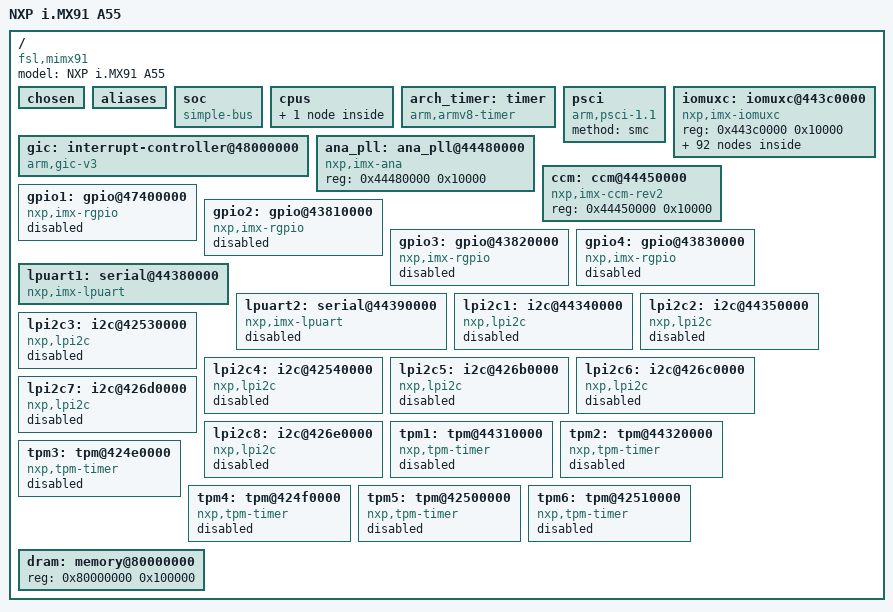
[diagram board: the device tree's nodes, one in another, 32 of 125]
/dts-v1/;

/* node '/' defined in zephyr/dts/common/skeleton.dtsi:9 */
/ {
	#address-cells = < 0x1 >;  /* in zephyr/dts/arm64/nxp/nxp_mimx9111.dtsi:16 */
	#size-cells = < 0x1 >;     /* in zephyr/dts/arm64/nxp/nxp_mimx9111.dtsi:17 */
	model = "NXP i.MX91 A55";  /* in zephyr/boards/nxp/imx91_qsb/imx91_qsb_mimx9111.dts:13 */
	compatible = "fsl,mimx91"; /* in zephyr/boards/nxp/imx91_qsb/imx91_qsb_mimx9111.dts:14 */

	/* node '/chosen' defined in zephyr/dts/common/skeleton.dtsi:13 */
	chosen {
		zephyr,console = &lpuart1;    /* in zephyr/boards/nxp/imx91_qsb/imx91_qsb_mimx9111.dts:17 */
		zephyr,shell-uart = &lpuart1; /* in zephyr/boards/nxp/imx91_qsb/imx91_qsb_mimx9111.dts:18 */
		zephyr,sram = &dram;          /* in zephyr/boards/nxp/imx91_qsb/imx91_qsb_mimx9111.dts:20 */
	};

	/* node '/aliases' defined in zephyr/dts/common/skeleton.dtsi:15 */
	aliases {
	};

	/* node '/soc' defined in zephyr/dts/arm64/armv8-a.dtsi:10 */
	soc {
		#address-cells = < 0x1 >;  /* in zephyr/dts/arm64/armv8-a.dtsi:11 */
		#size-cells = < 0x1 >;     /* in zephyr/dts/arm64/armv8-a.dtsi:12 */
		compatible = "simple-bus"; /* in zephyr/dts/arm64/armv8-a.dtsi:13 */
		ranges;                    /* in zephyr/dts/arm64/armv8-a.dtsi:14 */
	};

	/* node '/cpus' defined in zephyr/dts/arm64/nxp/nxp_mimx9111.dtsi:19 */
	cpus {
		#address-cells = < 0x1 >; /* in zephyr/dts/arm64/nxp/nxp_mimx9111.dtsi:20 */
		#size-cells = < 0x0 >;    /* in zephyr/dts/arm64/nxp/nxp_mimx9111.dtsi:21 */

		/* node '/cpus/cpu@0' defined in zephyr/dts/arm64/nxp/nxp_mimx9111.dtsi:23 */
		cpu@0 {
			device_type = "cpu";           /* in zephyr/dts/arm64/nxp/nxp_mimx9111.dtsi:24 */
			compatible = "arm,cortex-a55"; /* in zephyr/dts/arm64/nxp/nxp_mimx9111.dtsi:25 */
			reg = < 0x0 >;                 /* in zephyr/dts/arm64/nxp/nxp_mimx9111.dtsi:26 */
		};
	};

	/* node '/timer' defined in zephyr/dts/arm64/nxp/nxp_mimx9111.dtsi:30 */
	arch_timer: timer {
		compatible = "arm,armv8-timer";    /* in zephyr/dts/arm64/nxp/nxp_mimx9111.dtsi:31 */
		interrupts = < 0x1 0xd 0x2 0xa0 >,
		             < 0x1 0xe 0x2 0xa0 >,
		             < 0x1 0xb 0x2 0xa0 >,
		             < 0x1 0xa 0x2 0xa0 >; /* in zephyr/dts/arm64/nxp/nxp_mimx9111.dtsi:32 */
		interrupt-parent = < &gic >;       /* in zephyr/dts/arm64/nxp/nxp_mimx9111.dtsi:40 */
	};

	/* node '/psci' defined in zephyr/dts/arm64/nxp/nxp_mimx9111.dtsi:43 */
	psci: psci {
		compatible = "arm,psci-1.1"; /* in zephyr/dts/arm64/nxp/nxp_mimx9111.dtsi:44 */
		method = "smc";              /* in zephyr/dts/arm64/nxp/nxp_mimx9111.dtsi:45 */
	};

	/* node '/interrupt-controller@48000000' defined in zephyr/dts/arm64/nxp/nxp_mimx9111.dtsi:48 */
	gic: interrupt-controller@48000000 {
		compatible = "arm,gic-v3",
		             "arm,gic";       /* in zephyr/dts/arm64/nxp/nxp_mimx9111.dtsi:49 */
		reg = < 0x48000000 0x10000 >,
		      < 0x48040000 0xc0000 >; /* in zephyr/dts/arm64/nxp/nxp_mimx9111.dtsi:50 */
		interrupt-controller;         /* in zephyr/dts/arm64/nxp/nxp_mimx9111.dtsi:52 */
		#interrupt-cells = < 0x4 >;   /* in zephyr/dts/arm64/nxp/nxp_mimx9111.dtsi:53 */
		status = "okay";              /* in zephyr/dts/arm64/nxp/nxp_mimx9111.dtsi:54 */
		phandle = < 0x1 >;            /* in zephyr/dts/arm64/nxp/nxp_mimx9111.dtsi:40 */
	};

	/* node '/iomuxc@443c0000' defined in zephyr/dts/arm64/nxp/nxp_mimx9111.dtsi:57 */
	iomuxc: iomuxc@443c0000 {
		compatible = "nxp,imx-iomuxc"; /* in zephyr/dts/arm64/nxp/nxp_mimx9111.dtsi:58 */
		reg = < 0x443c0000 0x10000 >;  /* in zephyr/dts/arm64/nxp/nxp_mimx9111.dtsi:59 */
		status = "okay";               /* in zephyr/dts/arm64/nxp/nxp_mimx9111.dtsi:60 */

		/* node '/iomuxc@443c0000/pinctrl' defined in zephyr/dts/arm64/nxp/nxp_mimx9111.dtsi:62 */
		pinctrl: pinctrl {
			compatible = "nxp,imx93-pinctrl"; /* in zephyr/dts/arm64/nxp/nxp_mimx9111.dtsi:63 */
			status = "okay";                  /* in zephyr/dts/arm64/nxp/nxp_mimx9111.dtsi:64 */

			/* node '/iomuxc@443c0000/pinctrl/uart1_default' defined in zephyr/boards/nxp/imx91_qsb/imx91_qsb-pinctrl.dtsi:10 */
			uart1_default: uart1_default {
				phandle = < 0x5a >; /* in zephyr/boards/nxp/imx91_qsb/imx91_qsb_mimx9111.dts:32 */

				/* node '/iomuxc@443c0000/pinctrl/uart1_default/group0' defined in zephyr/boards/nxp/imx91_qsb/imx91_qsb-pinctrl.dtsi:11 */
				group0 {
					pinmux = < &iomuxc1_uart1_rxd_lpuart_rx_lpuart1_rx >,
					         < &iomuxc1_uart1_txd_lpuart_tx_lpuart1_tx >; /* in zephyr/boards/nxp/imx91_qsb/imx91_qsb-pinctrl.dtsi:12 */
					bias-pull-up;                                         /* in zephyr/boards/nxp/imx91_qsb/imx91_qsb-pinctrl.dtsi:14 */
					slew-rate = "slightly_fast";                          /* in zephyr/boards/nxp/imx91_qsb/imx91_qsb-pinctrl.dtsi:15 */
					drive-strength = "x5";                                /* in zephyr/boards/nxp/imx91_qsb/imx91_qsb-pinctrl.dtsi:16 */
				};
			};

			/* node '/iomuxc@443c0000/pinctrl/uart2_default' defined in zephyr/boards/nxp/imx91_qsb/imx91_qsb-pinctrl.dtsi:20 */
			uart2_default: uart2_default {

				/* node '/iomuxc@443c0000/pinctrl/uart2_default/group0' defined in zephyr/boards/nxp/imx91_qsb/imx91_qsb-pinctrl.dtsi:21 */
				group0 {
					pinmux = < &iomuxc1_uart2_rxd_lpuart_rx_lpuart2_rx >,
					         < &iomuxc1_uart2_txd_lpuart_tx_lpuart2_tx >; /* in zephyr/boards/nxp/imx91_qsb/imx91_qsb-pinctrl.dtsi:22 */
					bias-pull-up;                                         /* in zephyr/boards/nxp/imx91_qsb/imx91_qsb-pinctrl.dtsi:24 */
					slew-rate = "slightly_fast";                          /* in zephyr/boards/nxp/imx91_qsb/imx91_qsb-pinctrl.dtsi:25 */
					drive-strength = "x5";                                /* in zephyr/boards/nxp/imx91_qsb/imx91_qsb-pinctrl.dtsi:26 */
				};
			};
		};

		/* node '/iomuxc@443c0000/IOMUXC1_CCM_CLKO1_GPIO_IO_GPIO3_IO26' defined in modules/hal/nxp/dts/nxp/nxp_imx/mimx9111cvxxj-pinctrl.dtsi:26 */
		iomuxc1_ccm_clko1_gpio_io_gpio3_io26: IOMUXC1_CCM_CLKO1_GPIO_IO_GPIO3_IO26 {
			pinmux = < 0x443c0088 0x5 0x0 0x0 0x443c0238 >; /* in modules/hal/nxp/dts/nxp/nxp_imx/mimx9111cvxxj-pinctrl.dtsi:27 */
			phandle = < 0x46 >;                             /* in zephyr/dts/arm64/nxp/nxp_mimx9111.dtsi:355 */
		};

		/* node '/iomuxc@443c0000/IOMUXC1_DAP_TCLK_SWCLK_GPIO_IO_GPIO3_IO30' defined in modules/hal/nxp/dts/nxp/nxp_imx/mimx9111cvxxj-pinctrl.dtsi:32 */
		iomuxc1_dap_tclk_swclk_gpio_io_gpio3_io30: IOMUXC1_DAP_TCLK_SWCLK_GPIO_IO_GPIO3_IO30 {
			pinmux = < 0x443c0008 0x5 0x0 0x0 0x443c01b8 >; /* in modules/hal/nxp/dts/nxp/nxp_imx/mimx9111cvxxj-pinctrl.dtsi:33 */
			phandle = < 0x49 >;                             /* in zephyr/dts/arm64/nxp/nxp_mimx9111.dtsi:355 */
		};

		/* node '/iomuxc@443c0000/IOMUXC1_DAP_TDI_GPIO_IO_GPIO3_IO28' defined in modules/hal/nxp/dts/nxp/nxp_imx/mimx9111cvxxj-pinctrl.dtsi:47 */
		iomuxc1_dap_tdi_gpio_io_gpio3_io28: IOMUXC1_DAP_TDI_GPIO_IO_GPIO3_IO28 {
			pinmux = < 0x443c0000 0x5 0x0 0x0 0x443c01b0 >; /* in modules/hal/nxp/dts/nxp/nxp_imx/mimx9111cvxxj-pinctrl.dtsi:48 */
			phandle = < 0x47 >;                             /* in zephyr/dts/arm64/nxp/nxp_mimx9111.dtsi:355 */
		};

		/* node '/iomuxc@443c0000/IOMUXC1_DAP_TDO_TRACESWO_GPIO_IO_GPIO3_IO31' defined in modules/hal/nxp/dts/nxp/nxp_imx/mimx9111cvxxj-pinctrl.dtsi:65 */
		iomuxc1_dap_tdo_traceswo_gpio_io_gpio3_io31: IOMUXC1_DAP_TDO_TRACESWO_GPIO_IO_GPIO3_IO31 {
			pinmux = < 0x443c000c 0x5 0x0 0x0 0x443c01bc >; /* in modules/hal/nxp/dts/nxp/nxp_imx/mimx9111cvxxj-pinctrl.dtsi:66 */
			phandle = < 0x4a >;                             /* in zephyr/dts/arm64/nxp/nxp_mimx9111.dtsi:355 */
		};

		/* node '/iomuxc@443c0000/IOMUXC1_DAP_TMS_SWDIO_GPIO_IO_GPIO3_IO29' defined in modules/hal/nxp/dts/nxp/nxp_imx/mimx9111cvxxj-pinctrl.dtsi:80 */
		iomuxc1_dap_tms_swdio_gpio_io_gpio3_io29: IOMUXC1_DAP_TMS_SWDIO_GPIO_IO_GPIO3_IO29 {
			pinmux = < 0x443c0004 0x5 0x0 0x0 0x443c01b4 >; /* in modules/hal/nxp/dts/nxp/nxp_imx/mimx9111cvxxj-pinctrl.dtsi:81 */
			phandle = < 0x48 >;                             /* in zephyr/dts/arm64/nxp/nxp_mimx9111.dtsi:355 */
		};

		/* node '/iomuxc@443c0000/IOMUXC1_ENET1_MDC_GPIO_IO_GPIO4_IO0' defined in modules/hal/nxp/dts/nxp/nxp_imx/mimx9111cvxxj-pinctrl.dtsi:95 */
		iomuxc1_enet1_mdc_gpio_io_gpio4_io0: IOMUXC1_ENET1_MDC_GPIO_IO_GPIO4_IO0 {
			pinmux = < 0x443c0098 0x5 0x0 0x0 0x443c0248 >; /* in modules/hal/nxp/dts/nxp/nxp_imx/mimx9111cvxxj-pinctrl.dtsi:96 */
			phandle = < 0x4b >;                             /* in zephyr/dts/arm64/nxp/nxp_mimx9111.dtsi:390 */
		};

		/* node '/iomuxc@443c0000/IOMUXC1_ENET1_MDIO_GPIO_IO_GPIO4_IO1' defined in modules/hal/nxp/dts/nxp/nxp_imx/mimx9111cvxxj-pinctrl.dtsi:116 */
		iomuxc1_enet1_mdio_gpio_io_gpio4_io1: IOMUXC1_ENET1_MDIO_GPIO_IO_GPIO4_IO1 {
			pinmux = < 0x443c009c 0x5 0x0 0x0 0x443c024c >; /* in modules/hal/nxp/dts/nxp/nxp_imx/mimx9111cvxxj-pinctrl.dtsi:117 */
			phandle = < 0x4c >;                             /* in zephyr/dts/arm64/nxp/nxp_mimx9111.dtsi:390 */
		};

		/* node '/iomuxc@443c0000/IOMUXC1_ENET1_RD0_GPIO_IO_GPIO4_IO10' defined in modules/hal/nxp/dts/nxp/nxp_imx/mimx9111cvxxj-pinctrl.dtsi:137 */
		iomuxc1_enet1_rd0_gpio_io_gpio4_io10: IOMUXC1_ENET1_RD0_GPIO_IO_GPIO4_IO10 {
			pinmux = < 0x443c00c0 0x5 0x0 0x0 0x443c0270 >; /* in modules/hal/nxp/dts/nxp/nxp_imx/mimx9111cvxxj-pinctrl.dtsi:138 */
			phandle = < 0x55 >;                             /* in zephyr/dts/arm64/nxp/nxp_mimx9111.dtsi:390 */
		};

		/* node '/iomuxc@443c0000/IOMUXC1_ENET1_RD1_GPIO_IO_GPIO4_IO11' defined in modules/hal/nxp/dts/nxp/nxp_imx/mimx9111cvxxj-pinctrl.dtsi:149 */
		iomuxc1_enet1_rd1_gpio_io_gpio4_io11: IOMUXC1_ENET1_RD1_GPIO_IO_GPIO4_IO11 {
			pinmux = < 0x443c00c4 0x5 0x0 0x0 0x443c0274 >; /* in modules/hal/nxp/dts/nxp/nxp_imx/mimx9111cvxxj-pinctrl.dtsi:150 */
			phandle = < 0x56 >;                             /* in zephyr/dts/arm64/nxp/nxp_mimx9111.dtsi:390 */
		};

		/* node '/iomuxc@443c0000/IOMUXC1_ENET1_RD2_GPIO_IO_GPIO4_IO12' defined in modules/hal/nxp/dts/nxp/nxp_imx/mimx9111cvxxj-pinctrl.dtsi:164 */
		iomuxc1_enet1_rd2_gpio_io_gpio4_io12: IOMUXC1_ENET1_RD2_GPIO_IO_GPIO4_IO12 {
			pinmux = < 0x443c00c8 0x5 0x0 0x0 0x443c0278 >; /* in modules/hal/nxp/dts/nxp/nxp_imx/mimx9111cvxxj-pinctrl.dtsi:165 */
			phandle = < 0x57 >;                             /* in zephyr/dts/arm64/nxp/nxp_mimx9111.dtsi:390 */
		};

		/* node '/iomuxc@443c0000/IOMUXC1_ENET1_RD3_GPIO_IO_GPIO4_IO13' defined in modules/hal/nxp/dts/nxp/nxp_imx/mimx9111cvxxj-pinctrl.dtsi:176 */
		iomuxc1_enet1_rd3_gpio_io_gpio4_io13: IOMUXC1_ENET1_RD3_GPIO_IO_GPIO4_IO13 {
			pinmux = < 0x443c00cc 0x5 0x0 0x0 0x443c027c >; /* in modules/hal/nxp/dts/nxp/nxp_imx/mimx9111cvxxj-pinctrl.dtsi:177 */
			phandle = < 0x58 >;                             /* in zephyr/dts/arm64/nxp/nxp_mimx9111.dtsi:390 */
		};

		/* node '/iomuxc@443c0000/IOMUXC1_ENET1_RXC_GPIO_IO_GPIO4_IO9' defined in modules/hal/nxp/dts/nxp/nxp_imx/mimx9111cvxxj-pinctrl.dtsi:191 */
		iomuxc1_enet1_rxc_gpio_io_gpio4_io9: IOMUXC1_ENET1_RXC_GPIO_IO_GPIO4_IO9 {
			pinmux = < 0x443c00bc 0x5 0x0 0x0 0x443c026c >; /* in modules/hal/nxp/dts/nxp/nxp_imx/mimx9111cvxxj-pinctrl.dtsi:192 */
			phandle = < 0x54 >;                             /* in zephyr/dts/arm64/nxp/nxp_mimx9111.dtsi:390 */
		};

		/* node '/iomuxc@443c0000/IOMUXC1_ENET1_RX_CTL_GPIO_IO_GPIO4_IO8' defined in modules/hal/nxp/dts/nxp/nxp_imx/mimx9111cvxxj-pinctrl.dtsi:203 */
		iomuxc1_enet1_rx_ctl_gpio_io_gpio4_io8: IOMUXC1_ENET1_RX_CTL_GPIO_IO_GPIO4_IO8 {
			pinmux = < 0x443c00b8 0x5 0x0 0x0 0x443c0268 >; /* in modules/hal/nxp/dts/nxp/nxp_imx/mimx9111cvxxj-pinctrl.dtsi:204 */
			phandle = < 0x53 >;                             /* in zephyr/dts/arm64/nxp/nxp_mimx9111.dtsi:390 */
		};

		/* node '/iomuxc@443c0000/IOMUXC1_ENET1_TD0_GPIO_IO_GPIO4_IO5' defined in modules/hal/nxp/dts/nxp/nxp_imx/mimx9111cvxxj-pinctrl.dtsi:221 */
		iomuxc1_enet1_td0_gpio_io_gpio4_io5: IOMUXC1_ENET1_TD0_GPIO_IO_GPIO4_IO5 {
			pinmux = < 0x443c00ac 0x5 0x0 0x0 0x443c025c >; /* in modules/hal/nxp/dts/nxp/nxp_imx/mimx9111cvxxj-pinctrl.dtsi:222 */
			phandle = < 0x50 >;                             /* in zephyr/dts/arm64/nxp/nxp_mimx9111.dtsi:390 */
		};

		/* node '/iomuxc@443c0000/IOMUXC1_ENET1_TD1_GPIO_IO_GPIO4_IO4' defined in modules/hal/nxp/dts/nxp/nxp_imx/mimx9111cvxxj-pinctrl.dtsi:233 */
		iomuxc1_enet1_td1_gpio_io_gpio4_io4: IOMUXC1_ENET1_TD1_GPIO_IO_GPIO4_IO4 {
			pinmux = < 0x443c00a8 0x5 0x0 0x0 0x443c0258 >; /* in modules/hal/nxp/dts/nxp/nxp_imx/mimx9111cvxxj-pinctrl.dtsi:234 */
			phandle = < 0x4f >;                             /* in zephyr/dts/arm64/nxp/nxp_mimx9111.dtsi:390 */
		};

		/* node '/iomuxc@443c0000/IOMUXC1_ENET1_TD2_GPIO_IO_GPIO4_IO3' defined in modules/hal/nxp/dts/nxp/nxp_imx/mimx9111cvxxj-pinctrl.dtsi:260 */
		iomuxc1_enet1_td2_gpio_io_gpio4_io3: IOMUXC1_ENET1_TD2_GPIO_IO_GPIO4_IO3 {
			pinmux = < 0x443c00a4 0x5 0x0 0x0 0x443c0254 >; /* in modules/hal/nxp/dts/nxp/nxp_imx/mimx9111cvxxj-pinctrl.dtsi:261 */
			phandle = < 0x4e >;                             /* in zephyr/dts/arm64/nxp/nxp_mimx9111.dtsi:390 */
		};

		/* node '/iomuxc@443c0000/IOMUXC1_ENET1_TD3_GPIO_IO_GPIO4_IO2' defined in modules/hal/nxp/dts/nxp/nxp_imx/mimx9111cvxxj-pinctrl.dtsi:278 */
		iomuxc1_enet1_td3_gpio_io_gpio4_io2: IOMUXC1_ENET1_TD3_GPIO_IO_GPIO4_IO2 {
			pinmux = < 0x443c00a0 0x5 0x0 0x0 0x443c0250 >; /* in modules/hal/nxp/dts/nxp/nxp_imx/mimx9111cvxxj-pinctrl.dtsi:279 */
			phandle = < 0x4d >;                             /* in zephyr/dts/arm64/nxp/nxp_mimx9111.dtsi:390 */
		};

		/* node '/iomuxc@443c0000/IOMUXC1_ENET1_TXC_GPIO_IO_GPIO4_IO7' defined in modules/hal/nxp/dts/nxp/nxp_imx/mimx9111cvxxj-pinctrl.dtsi:296 */
		iomuxc1_enet1_txc_gpio_io_gpio4_io7: IOMUXC1_ENET1_TXC_GPIO_IO_GPIO4_IO7 {
			pinmux = < 0x443c00b4 0x5 0x0 0x0 0x443c0264 >; /* in modules/hal/nxp/dts/nxp/nxp_imx/mimx9111cvxxj-pinctrl.dtsi:297 */
			phandle = < 0x52 >;                             /* in zephyr/dts/arm64/nxp/nxp_mimx9111.dtsi:390 */
		};

		/* node '/iomuxc@443c0000/IOMUXC1_ENET1_TX_CTL_GPIO_IO_GPIO4_IO6' defined in modules/hal/nxp/dts/nxp/nxp_imx/mimx9111cvxxj-pinctrl.dtsi:308 */
		iomuxc1_enet1_tx_ctl_gpio_io_gpio4_io6: IOMUXC1_ENET1_TX_CTL_GPIO_IO_GPIO4_IO6 {
			pinmux = < 0x443c00b0 0x5 0x0 0x0 0x443c0260 >; /* in modules/hal/nxp/dts/nxp/nxp_imx/mimx9111cvxxj-pinctrl.dtsi:309 */
			phandle = < 0x51 >;                             /* in zephyr/dts/arm64/nxp/nxp_mimx9111.dtsi:390 */
		};

		/* node '/iomuxc@443c0000/IOMUXC1_GPIO_IO00_GPIO_IO_GPIO2_IO0' defined in modules/hal/nxp/dts/nxp/nxp_imx/mimx9111cvxxj-pinctrl.dtsi:320 */
		iomuxc1_gpio_io00_gpio_io_gpio2_io0: IOMUXC1_GPIO_IO00_GPIO_IO_GPIO2_IO0 {
			pinmux = < 0x443c0010 0x0 0x0 0x0 0x443c01c0 >; /* in modules/hal/nxp/dts/nxp/nxp_imx/mimx9111cvxxj-pinctrl.dtsi:321 */
			phandle = < 0x16 >;                             /* in zephyr/dts/arm64/nxp/nxp_mimx9111.dtsi:330 */
		};

		/* node '/iomuxc@443c0000/IOMUXC1_GPIO_IO01_GPIO_IO_GPIO2_IO1' defined in modules/hal/nxp/dts/nxp/nxp_imx/mimx9111cvxxj-pinctrl.dtsi:344 */
		iomuxc1_gpio_io01_gpio_io_gpio2_io1: IOMUXC1_GPIO_IO01_GPIO_IO_GPIO2_IO1 {
			pinmux = < 0x443c0014 0x0 0x0 0x0 0x443c01c4 >; /* in modules/hal/nxp/dts/nxp/nxp_imx/mimx9111cvxxj-pinctrl.dtsi:345 */
			phandle = < 0x17 >;                             /* in zephyr/dts/arm64/nxp/nxp_mimx9111.dtsi:330 */
		};

		/* node '/iomuxc@443c0000/IOMUXC1_GPIO_IO02_GPIO_IO_GPIO2_IO2' defined in modules/hal/nxp/dts/nxp/nxp_imx/mimx9111cvxxj-pinctrl.dtsi:368 */
		iomuxc1_gpio_io02_gpio_io_gpio2_io2: IOMUXC1_GPIO_IO02_GPIO_IO_GPIO2_IO2 {
			pinmux = < 0x443c0018 0x0 0x0 0x0 0x443c01c8 >; /* in modules/hal/nxp/dts/nxp/nxp_imx/mimx9111cvxxj-pinctrl.dtsi:369 */
			phandle = < 0x18 >;                             /* in zephyr/dts/arm64/nxp/nxp_mimx9111.dtsi:330 */
		};

		/* node '/iomuxc@443c0000/IOMUXC1_GPIO_IO03_GPIO_IO_GPIO2_IO3' defined in modules/hal/nxp/dts/nxp/nxp_imx/mimx9111cvxxj-pinctrl.dtsi:392 */
		iomuxc1_gpio_io03_gpio_io_gpio2_io3: IOMUXC1_GPIO_IO03_GPIO_IO_GPIO2_IO3 {
			pinmux = < 0x443c001c 0x0 0x0 0x0 0x443c01cc >; /* in modules/hal/nxp/dts/nxp/nxp_imx/mimx9111cvxxj-pinctrl.dtsi:393 */
			phandle = < 0x19 >;                             /* in zephyr/dts/arm64/nxp/nxp_mimx9111.dtsi:330 */
		};

		/* node '/iomuxc@443c0000/IOMUXC1_GPIO_IO04_GPIO_IO_GPIO2_IO4' defined in modules/hal/nxp/dts/nxp/nxp_imx/mimx9111cvxxj-pinctrl.dtsi:416 */
		iomuxc1_gpio_io04_gpio_io_gpio2_io4: IOMUXC1_GPIO_IO04_GPIO_IO_GPIO2_IO4 {
			pinmux = < 0x443c0020 0x0 0x0 0x0 0x443c01d0 >; /* in modules/hal/nxp/dts/nxp/nxp_imx/mimx9111cvxxj-pinctrl.dtsi:417 */
			phandle = < 0x1a >;                             /* in zephyr/dts/arm64/nxp/nxp_mimx9111.dtsi:330 */
		};

		/* node '/iomuxc@443c0000/IOMUXC1_GPIO_IO05_GPIO_IO_GPIO2_IO5' defined in modules/hal/nxp/dts/nxp/nxp_imx/mimx9111cvxxj-pinctrl.dtsi:440 */
		iomuxc1_gpio_io05_gpio_io_gpio2_io5: IOMUXC1_GPIO_IO05_GPIO_IO_GPIO2_IO5 {
			pinmux = < 0x443c0024 0x0 0x0 0x0 0x443c01d4 >; /* in modules/hal/nxp/dts/nxp/nxp_imx/mimx9111cvxxj-pinctrl.dtsi:441 */
			phandle = < 0x1b >;                             /* in zephyr/dts/arm64/nxp/nxp_mimx9111.dtsi:330 */
		};

		/* node '/iomuxc@443c0000/IOMUXC1_GPIO_IO06_GPIO_IO_GPIO2_IO6' defined in modules/hal/nxp/dts/nxp/nxp_imx/mimx9111cvxxj-pinctrl.dtsi:464 */
		iomuxc1_gpio_io06_gpio_io_gpio2_io6: IOMUXC1_GPIO_IO06_GPIO_IO_GPIO2_IO6 {
			pinmux = < 0x443c0028 0x0 0x0 0x0 0x443c01d8 >; /* in modules/hal/nxp/dts/nxp/nxp_imx/mimx9111cvxxj-pinctrl.dtsi:465 */
			phandle = < 0x1c >;                             /* in zephyr/dts/arm64/nxp/nxp_mimx9111.dtsi:330 */
		};

		/* node '/iomuxc@443c0000/IOMUXC1_GPIO_IO07_GPIO_IO_GPIO2_IO7' defined in modules/hal/nxp/dts/nxp/nxp_imx/mimx9111cvxxj-pinctrl.dtsi:488 */
		iomuxc1_gpio_io07_gpio_io_gpio2_io7: IOMUXC1_GPIO_IO07_GPIO_IO_GPIO2_IO7 {
			pinmux = < 0x443c002c 0x0 0x0 0x0 0x443c01dc >; /* in modules/hal/nxp/dts/nxp/nxp_imx/mimx9111cvxxj-pinctrl.dtsi:489 */
			phandle = < 0x1d >;                             /* in zephyr/dts/arm64/nxp/nxp_mimx9111.dtsi:330 */
		};

		/* node '/iomuxc@443c0000/IOMUXC1_GPIO_IO08_GPIO_IO_GPIO2_IO8' defined in modules/hal/nxp/dts/nxp/nxp_imx/mimx9111cvxxj-pinctrl.dtsi:512 */
		iomuxc1_gpio_io08_gpio_io_gpio2_io8: IOMUXC1_GPIO_IO08_GPIO_IO_GPIO2_IO8 {
			pinmux = < 0x443c0030 0x0 0x0 0x0 0x443c01e0 >; /* in modules/hal/nxp/dts/nxp/nxp_imx/mimx9111cvxxj-pinctrl.dtsi:513 */
			phandle = < 0x1e >;                             /* in zephyr/dts/arm64/nxp/nxp_mimx9111.dtsi:330 */
		};

		/* node '/iomuxc@443c0000/IOMUXC1_GPIO_IO09_GPIO_IO_GPIO2_IO9' defined in modules/hal/nxp/dts/nxp/nxp_imx/mimx9111cvxxj-pinctrl.dtsi:536 */
		iomuxc1_gpio_io09_gpio_io_gpio2_io9: IOMUXC1_GPIO_IO09_GPIO_IO_GPIO2_IO9 {
			pinmux = < 0x443c0034 0x0 0x0 0x0 0x443c01e4 >; /* in modules/hal/nxp/dts/nxp/nxp_imx/mimx9111cvxxj-pinctrl.dtsi:537 */
			phandle = < 0x1f >;                             /* in zephyr/dts/arm64/nxp/nxp_mimx9111.dtsi:330 */
		};

		/* node '/iomuxc@443c0000/IOMUXC1_GPIO_IO10_GPIO_IO_GPIO2_IO10' defined in modules/hal/nxp/dts/nxp/nxp_imx/mimx9111cvxxj-pinctrl.dtsi:560 */
		iomuxc1_gpio_io10_gpio_io_gpio2_io10: IOMUXC1_GPIO_IO10_GPIO_IO_GPIO2_IO10 {
			pinmux = < 0x443c0038 0x0 0x0 0x0 0x443c01e8 >; /* in modules/hal/nxp/dts/nxp/nxp_imx/mimx9111cvxxj-pinctrl.dtsi:561 */
			phandle = < 0x20 >;                             /* in zephyr/dts/arm64/nxp/nxp_mimx9111.dtsi:330 */
		};

		/* node '/iomuxc@443c0000/IOMUXC1_GPIO_IO11_GPIO_IO_GPIO2_IO11' defined in modules/hal/nxp/dts/nxp/nxp_imx/mimx9111cvxxj-pinctrl.dtsi:584 */
		iomuxc1_gpio_io11_gpio_io_gpio2_io11: IOMUXC1_GPIO_IO11_GPIO_IO_GPIO2_IO11 {
			pinmux = < 0x443c003c 0x0 0x0 0x0 0x443c01ec >; /* in modules/hal/nxp/dts/nxp/nxp_imx/mimx9111cvxxj-pinctrl.dtsi:585 */
			phandle = < 0x21 >;                             /* in zephyr/dts/arm64/nxp/nxp_mimx9111.dtsi:330 */
		};

		/* node '/iomuxc@443c0000/IOMUXC1_GPIO_IO12_GPIO_IO_GPIO2_IO12' defined in modules/hal/nxp/dts/nxp/nxp_imx/mimx9111cvxxj-pinctrl.dtsi:605 */
		iomuxc1_gpio_io12_gpio_io_gpio2_io12: IOMUXC1_GPIO_IO12_GPIO_IO_GPIO2_IO12 {
			pinmux = < 0x443c0040 0x0 0x0 0x0 0x443c01f0 >; /* in modules/hal/nxp/dts/nxp/nxp_imx/mimx9111cvxxj-pinctrl.dtsi:606 */
			phandle = < 0x22 >;                             /* in zephyr/dts/arm64/nxp/nxp_mimx9111.dtsi:330 */
		};

		/* node '/iomuxc@443c0000/IOMUXC1_GPIO_IO13_GPIO_IO_GPIO2_IO13' defined in modules/hal/nxp/dts/nxp/nxp_imx/mimx9111cvxxj-pinctrl.dtsi:632 */
		iomuxc1_gpio_io13_gpio_io_gpio2_io13: IOMUXC1_GPIO_IO13_GPIO_IO_GPIO2_IO13 {
			pinmux = < 0x443c0044 0x0 0x0 0x0 0x443c01f4 >; /* in modules/hal/nxp/dts/nxp/nxp_imx/mimx9111cvxxj-pinctrl.dtsi:633 */
			phandle = < 0x23 >;                             /* in zephyr/dts/arm64/nxp/nxp_mimx9111.dtsi:330 */
		};

		/* node '/iomuxc@443c0000/IOMUXC1_GPIO_IO14_GPIO_IO_GPIO2_IO14' defined in modules/hal/nxp/dts/nxp/nxp_imx/mimx9111cvxxj-pinctrl.dtsi:656 */
		iomuxc1_gpio_io14_gpio_io_gpio2_io14: IOMUXC1_GPIO_IO14_GPIO_IO_GPIO2_IO14 {
			pinmux = < 0x443c0048 0x0 0x0 0x0 0x443c01f8 >; /* in modules/hal/nxp/dts/nxp/nxp_imx/mimx9111cvxxj-pinctrl.dtsi:657 */
			phandle = < 0x24 >;                             /* in zephyr/dts/arm64/nxp/nxp_mimx9111.dtsi:330 */
		};

		/* node '/iomuxc@443c0000/IOMUXC1_GPIO_IO15_GPIO_IO_GPIO2_IO15' defined in modules/hal/nxp/dts/nxp/nxp_imx/mimx9111cvxxj-pinctrl.dtsi:680 */
		iomuxc1_gpio_io15_gpio_io_gpio2_io15: IOMUXC1_GPIO_IO15_GPIO_IO_GPIO2_IO15 {
			pinmux = < 0x443c004c 0x0 0x0 0x0 0x443c01fc >; /* in modules/hal/nxp/dts/nxp/nxp_imx/mimx9111cvxxj-pinctrl.dtsi:681 */
			phandle = < 0x25 >;                             /* in zephyr/dts/arm64/nxp/nxp_mimx9111.dtsi:330 */
		};

		/* node '/iomuxc@443c0000/IOMUXC1_GPIO_IO16_GPIO_IO_GPIO2_IO16' defined in modules/hal/nxp/dts/nxp/nxp_imx/mimx9111cvxxj-pinctrl.dtsi:704 */
		iomuxc1_gpio_io16_gpio_io_gpio2_io16: IOMUXC1_GPIO_IO16_GPIO_IO_GPIO2_IO16 {
			pinmux = < 0x443c0050 0x0 0x0 0x0 0x443c0200 >; /* in modules/hal/nxp/dts/nxp/nxp_imx/mimx9111cvxxj-pinctrl.dtsi:705 */
			phandle = < 0x26 >;                             /* in zephyr/dts/arm64/nxp/nxp_mimx9111.dtsi:330 */
		};

		/* node '/iomuxc@443c0000/IOMUXC1_GPIO_IO17_GPIO_IO_GPIO2_IO17' defined in modules/hal/nxp/dts/nxp/nxp_imx/mimx9111cvxxj-pinctrl.dtsi:728 */
		iomuxc1_gpio_io17_gpio_io_gpio2_io17: IOMUXC1_GPIO_IO17_GPIO_IO_GPIO2_IO17 {
			pinmux = < 0x443c0054 0x0 0x0 0x0 0x443c0204 >; /* in modules/hal/nxp/dts/nxp/nxp_imx/mimx9111cvxxj-pinctrl.dtsi:729 */
			phandle = < 0x27 >;                             /* in zephyr/dts/arm64/nxp/nxp_mimx9111.dtsi:330 */
		};

		/* node '/iomuxc@443c0000/IOMUXC1_GPIO_IO18_GPIO_IO_GPIO2_IO18' defined in modules/hal/nxp/dts/nxp/nxp_imx/mimx9111cvxxj-pinctrl.dtsi:752 */
		iomuxc1_gpio_io18_gpio_io_gpio2_io18: IOMUXC1_GPIO_IO18_GPIO_IO_GPIO2_IO18 {
			pinmux = < 0x443c0058 0x0 0x0 0x0 0x443c0208 >; /* in modules/hal/nxp/dts/nxp/nxp_imx/mimx9111cvxxj-pinctrl.dtsi:753 */
			phandle = < 0x28 >;                             /* in zephyr/dts/arm64/nxp/nxp_mimx9111.dtsi:330 */
		};

		/* node '/iomuxc@443c0000/IOMUXC1_GPIO_IO19_GPIO_IO_GPIO2_IO19' defined in modules/hal/nxp/dts/nxp/nxp_imx/mimx9111cvxxj-pinctrl.dtsi:773 */
		iomuxc1_gpio_io19_gpio_io_gpio2_io19: IOMUXC1_GPIO_IO19_GPIO_IO_GPIO2_IO19 {
			pinmux = < 0x443c005c 0x0 0x0 0x0 0x443c020c >; /* in modules/hal/nxp/dts/nxp/nxp_imx/mimx9111cvxxj-pinctrl.dtsi:774 */
			phandle = < 0x29 >;                             /* in zephyr/dts/arm64/nxp/nxp_mimx9111.dtsi:330 */
		};

		/* node '/iomuxc@443c0000/IOMUXC1_GPIO_IO20_GPIO_IO_GPIO2_IO20' defined in modules/hal/nxp/dts/nxp/nxp_imx/mimx9111cvxxj-pinctrl.dtsi:800 */
		iomuxc1_gpio_io20_gpio_io_gpio2_io20: IOMUXC1_GPIO_IO20_GPIO_IO_GPIO2_IO20 {
			pinmux = < 0x443c0060 0x0 0x0 0x0 0x443c0210 >; /* in modules/hal/nxp/dts/nxp/nxp_imx/mimx9111cvxxj-pinctrl.dtsi:801 */
			phandle = < 0x2a >;                             /* in zephyr/dts/arm64/nxp/nxp_mimx9111.dtsi:330 */
		};

		/* node '/iomuxc@443c0000/IOMUXC1_GPIO_IO21_GPIO_IO_GPIO2_IO21' defined in modules/hal/nxp/dts/nxp/nxp_imx/mimx9111cvxxj-pinctrl.dtsi:821 */
		iomuxc1_gpio_io21_gpio_io_gpio2_io21: IOMUXC1_GPIO_IO21_GPIO_IO_GPIO2_IO21 {
			pinmux = < 0x443c0064 0x0 0x0 0x0 0x443c0214 >; /* in modules/hal/nxp/dts/nxp/nxp_imx/mimx9111cvxxj-pinctrl.dtsi:822 */
			phandle = < 0x2b >;                             /* in zephyr/dts/arm64/nxp/nxp_mimx9111.dtsi:330 */
		};

		/* node '/iomuxc@443c0000/IOMUXC1_I2C1_SCL_GPIO_IO_GPIO1_IO0' defined in modules/hal/nxp/dts/nxp/nxp_imx/mimx9111cvxxj-pinctrl.dtsi:845 */
		iomuxc1_i2c1_scl_gpio_io_gpio1_io0: IOMUXC1_I2C1_SCL_GPIO_IO_GPIO1_IO0 {
			pinmux = < 0x443c0170 0x5 0x0 0x0 0x443c0320 >; /* in modules/hal/nxp/dts/nxp/nxp_imx/mimx9111cvxxj-pinctrl.dtsi:846 */
			phandle = < 0x6 >;                              /* in zephyr/dts/arm64/nxp/nxp_mimx9111.dtsi:311 */
		};

		/* node '/iomuxc@443c0000/IOMUXC1_I2C1_SDA_GPIO_IO_GPIO1_IO1' defined in modules/hal/nxp/dts/nxp/nxp_imx/mimx9111cvxxj-pinctrl.dtsi:860 */
		iomuxc1_i2c1_sda_gpio_io_gpio1_io1: IOMUXC1_I2C1_SDA_GPIO_IO_GPIO1_IO1 {
			pinmux = < 0x443c0174 0x5 0x0 0x0 0x443c0324 >; /* in modules/hal/nxp/dts/nxp/nxp_imx/mimx9111cvxxj-pinctrl.dtsi:861 */
			phandle = < 0x7 >;                              /* in zephyr/dts/arm64/nxp/nxp_mimx9111.dtsi:311 */
		};

		/* node '/iomuxc@443c0000/IOMUXC1_I2C2_SCL_GPIO_IO_GPIO1_IO2' defined in modules/hal/nxp/dts/nxp/nxp_imx/mimx9111cvxxj-pinctrl.dtsi:875 */
		iomuxc1_i2c2_scl_gpio_io_gpio1_io2: IOMUXC1_I2C2_SCL_GPIO_IO_GPIO1_IO2 {
			pinmux = < 0x443c0178 0x5 0x0 0x0 0x443c0328 >; /* in modules/hal/nxp/dts/nxp/nxp_imx/mimx9111cvxxj-pinctrl.dtsi:876 */
			phandle = < 0x8 >;                              /* in zephyr/dts/arm64/nxp/nxp_mimx9111.dtsi:311 */
		};

		/* node '/iomuxc@443c0000/IOMUXC1_I2C2_SDA_GPIO_IO_GPIO1_IO3' defined in modules/hal/nxp/dts/nxp/nxp_imx/mimx9111cvxxj-pinctrl.dtsi:896 */
		iomuxc1_i2c2_sda_gpio_io_gpio1_io3: IOMUXC1_I2C2_SDA_GPIO_IO_GPIO1_IO3 {
			pinmux = < 0x443c017c 0x5 0x0 0x0 0x443c032c >; /* in modules/hal/nxp/dts/nxp/nxp_imx/mimx9111cvxxj-pinctrl.dtsi:897 */
			phandle = < 0x9 >;                              /* in zephyr/dts/arm64/nxp/nxp_mimx9111.dtsi:311 */
		};

		/* node '/iomuxc@443c0000/IOMUXC1_PDM_BIT_STREAM0_GPIO_IO_GPIO1_IO9' defined in modules/hal/nxp/dts/nxp/nxp_imx/mimx9111cvxxj-pinctrl.dtsi:914 */
		iomuxc1_pdm_bit_stream0_gpio_io_gpio1_io9: IOMUXC1_PDM_BIT_STREAM0_GPIO_IO_GPIO1_IO9 {
			pinmux = < 0x443c0194 0x5 0x0 0x0 0x443c0344 >; /* in modules/hal/nxp/dts/nxp/nxp_imx/mimx9111cvxxj-pinctrl.dtsi:915 */
			phandle = < 0xf >;                              /* in zephyr/dts/arm64/nxp/nxp_mimx9111.dtsi:311 */
		};

		/* node '/iomuxc@443c0000/IOMUXC1_PDM_BIT_STREAM1_GPIO_IO_GPIO1_IO10' defined in modules/hal/nxp/dts/nxp/nxp_imx/mimx9111cvxxj-pinctrl.dtsi:932 */
		iomuxc1_pdm_bit_stream1_gpio_io_gpio1_io10: IOMUXC1_PDM_BIT_STREAM1_GPIO_IO_GPIO1_IO10 {
			pinmux = < 0x443c0198 0x5 0x0 0x0 0x443c0348 >; /* in modules/hal/nxp/dts/nxp/nxp_imx/mimx9111cvxxj-pinctrl.dtsi:933 */
			phandle = < 0x10 >;                             /* in zephyr/dts/arm64/nxp/nxp_mimx9111.dtsi:311 */
		};

		/* node '/iomuxc@443c0000/IOMUXC1_PDM_CLK_GPIO_IO_GPIO1_IO8' defined in modules/hal/nxp/dts/nxp/nxp_imx/mimx9111cvxxj-pinctrl.dtsi:950 */
		iomuxc1_pdm_clk_gpio_io_gpio1_io8: IOMUXC1_PDM_CLK_GPIO_IO_GPIO1_IO8 {
			pinmux = < 0x443c0190 0x5 0x0 0x0 0x443c0340 >; /* in modules/hal/nxp/dts/nxp/nxp_imx/mimx9111cvxxj-pinctrl.dtsi:951 */
			phandle = < 0xe >;                              /* in zephyr/dts/arm64/nxp/nxp_mimx9111.dtsi:311 */
		};

		/* node '/iomuxc@443c0000/IOMUXC1_SAI1_RXD0_GPIO_IO_GPIO1_IO14' defined in modules/hal/nxp/dts/nxp/nxp_imx/mimx9111cvxxj-pinctrl.dtsi:962 */
		iomuxc1_sai1_rxd0_gpio_io_gpio1_io14: IOMUXC1_SAI1_RXD0_GPIO_IO_GPIO1_IO14 {
			pinmux = < 0x443c01a8 0x5 0x0 0x0 0x443c0358 >; /* in modules/hal/nxp/dts/nxp/nxp_imx/mimx9111cvxxj-pinctrl.dtsi:963 */
			phandle = < 0x14 >;                             /* in zephyr/dts/arm64/nxp/nxp_mimx9111.dtsi:311 */
		};

		/* node '/iomuxc@443c0000/IOMUXC1_SAI1_TXC_GPIO_IO_GPIO1_IO12' defined in modules/hal/nxp/dts/nxp/nxp_imx/mimx9111cvxxj-pinctrl.dtsi:983 */
		iomuxc1_sai1_txc_gpio_io_gpio1_io12: IOMUXC1_SAI1_TXC_GPIO_IO_GPIO1_IO12 {
			pinmux = < 0x443c01a0 0x5 0x0 0x0 0x443c0350 >; /* in modules/hal/nxp/dts/nxp/nxp_imx/mimx9111cvxxj-pinctrl.dtsi:984 */
			phandle = < 0x12 >;                             /* in zephyr/dts/arm64/nxp/nxp_mimx9111.dtsi:311 */
		};

		/* node '/iomuxc@443c0000/IOMUXC1_SAI1_TXD0_GPIO_IO_GPIO1_IO13' defined in modules/hal/nxp/dts/nxp/nxp_imx/mimx9111cvxxj-pinctrl.dtsi:1001 */
		iomuxc1_sai1_txd0_gpio_io_gpio1_io13: IOMUXC1_SAI1_TXD0_GPIO_IO_GPIO1_IO13 {
			pinmux = < 0x443c01a4 0x5 0x0 0x0 0x443c0354 >; /* in modules/hal/nxp/dts/nxp/nxp_imx/mimx9111cvxxj-pinctrl.dtsi:1002 */
			phandle = < 0x13 >;                             /* in zephyr/dts/arm64/nxp/nxp_mimx9111.dtsi:311 */
		};

		/* node '/iomuxc@443c0000/IOMUXC1_SAI1_TXFS_GPIO_IO_GPIO1_IO11' defined in modules/hal/nxp/dts/nxp/nxp_imx/mimx9111cvxxj-pinctrl.dtsi:1019 */
		iomuxc1_sai1_txfs_gpio_io_gpio1_io11: IOMUXC1_SAI1_TXFS_GPIO_IO_GPIO1_IO11 {
			pinmux = < 0x443c019c 0x5 0x0 0x0 0x443c034c >; /* in modules/hal/nxp/dts/nxp/nxp_imx/mimx9111cvxxj-pinctrl.dtsi:1020 */
			phandle = < 0x11 >;                             /* in zephyr/dts/arm64/nxp/nxp_mimx9111.dtsi:311 */
		};

		/* node '/iomuxc@443c0000/IOMUXC1_SD1_CLK_GPIO_IO_GPIO3_IO8' defined in modules/hal/nxp/dts/nxp/nxp_imx/mimx9111cvxxj-pinctrl.dtsi:1040 */
		iomuxc1_sd1_clk_gpio_io_gpio3_io8: IOMUXC1_SD1_CLK_GPIO_IO_GPIO3_IO8 {
			pinmux = < 0x443c0108 0x5 0x0 0x0 0x443c02b8 >; /* in modules/hal/nxp/dts/nxp/nxp_imx/mimx9111cvxxj-pinctrl.dtsi:1041 */
			phandle = < 0x34 >;                             /* in zephyr/dts/arm64/nxp/nxp_mimx9111.dtsi:355 */
		};

		/* node '/iomuxc@443c0000/IOMUXC1_SD1_CMD_GPIO_IO_GPIO3_IO9' defined in modules/hal/nxp/dts/nxp/nxp_imx/mimx9111cvxxj-pinctrl.dtsi:1052 */
		iomuxc1_sd1_cmd_gpio_io_gpio3_io9: IOMUXC1_SD1_CMD_GPIO_IO_GPIO3_IO9 {
			pinmux = < 0x443c010c 0x5 0x0 0x0 0x443c02bc >; /* in modules/hal/nxp/dts/nxp/nxp_imx/mimx9111cvxxj-pinctrl.dtsi:1053 */
			phandle = < 0x35 >;                             /* in zephyr/dts/arm64/nxp/nxp_mimx9111.dtsi:355 */
		};

		/* node '/iomuxc@443c0000/IOMUXC1_SD1_DATA0_GPIO_IO_GPIO3_IO10' defined in modules/hal/nxp/dts/nxp/nxp_imx/mimx9111cvxxj-pinctrl.dtsi:1064 */
		iomuxc1_sd1_data0_gpio_io_gpio3_io10: IOMUXC1_SD1_DATA0_GPIO_IO_GPIO3_IO10 {
			pinmux = < 0x443c0110 0x5 0x0 0x0 0x443c02c0 >; /* in modules/hal/nxp/dts/nxp/nxp_imx/mimx9111cvxxj-pinctrl.dtsi:1065 */
			phandle = < 0x36 >;                             /* in zephyr/dts/arm64/nxp/nxp_mimx9111.dtsi:355 */
		};

		/* node '/iomuxc@443c0000/IOMUXC1_SD1_DATA1_GPIO_IO_GPIO3_IO11' defined in modules/hal/nxp/dts/nxp/nxp_imx/mimx9111cvxxj-pinctrl.dtsi:1076 */
		iomuxc1_sd1_data1_gpio_io_gpio3_io11: IOMUXC1_SD1_DATA1_GPIO_IO_GPIO3_IO11 {
			pinmux = < 0x443c0114 0x5 0x0 0x0 0x443c02c4 >; /* in modules/hal/nxp/dts/nxp/nxp_imx/mimx9111cvxxj-pinctrl.dtsi:1077 */
			phandle = < 0x37 >;                             /* in zephyr/dts/arm64/nxp/nxp_mimx9111.dtsi:355 */
		};

		/* node '/iomuxc@443c0000/IOMUXC1_SD1_DATA2_GPIO_IO_GPIO3_IO12' defined in modules/hal/nxp/dts/nxp/nxp_imx/mimx9111cvxxj-pinctrl.dtsi:1088 */
		iomuxc1_sd1_data2_gpio_io_gpio3_io12: IOMUXC1_SD1_DATA2_GPIO_IO_GPIO3_IO12 {
			pinmux = < 0x443c0118 0x5 0x0 0x0 0x443c02c8 >; /* in modules/hal/nxp/dts/nxp/nxp_imx/mimx9111cvxxj-pinctrl.dtsi:1089 */
			phandle = < 0x38 >;                             /* in zephyr/dts/arm64/nxp/nxp_mimx9111.dtsi:355 */
		};

		/* node '/iomuxc@443c0000/IOMUXC1_SD1_DATA3_GPIO_IO_GPIO3_IO13' defined in modules/hal/nxp/dts/nxp/nxp_imx/mimx9111cvxxj-pinctrl.dtsi:1103 */
		iomuxc1_sd1_data3_gpio_io_gpio3_io13: IOMUXC1_SD1_DATA3_GPIO_IO_GPIO3_IO13 {
			pinmux = < 0x443c011c 0x5 0x0 0x0 0x443c02cc >; /* in modules/hal/nxp/dts/nxp/nxp_imx/mimx9111cvxxj-pinctrl.dtsi:1104 */
			phandle = < 0x39 >;                             /* in zephyr/dts/arm64/nxp/nxp_mimx9111.dtsi:355 */
		};

		/* node '/iomuxc@443c0000/IOMUXC1_SD1_DATA4_GPIO_IO_GPIO3_IO14' defined in modules/hal/nxp/dts/nxp/nxp_imx/mimx9111cvxxj-pinctrl.dtsi:1118 */
		iomuxc1_sd1_data4_gpio_io_gpio3_io14: IOMUXC1_SD1_DATA4_GPIO_IO_GPIO3_IO14 {
			pinmux = < 0x443c0120 0x5 0x0 0x0 0x443c02d0 >; /* in modules/hal/nxp/dts/nxp/nxp_imx/mimx9111cvxxj-pinctrl.dtsi:1119 */
			phandle = < 0x3a >;                             /* in zephyr/dts/arm64/nxp/nxp_mimx9111.dtsi:355 */
		};

		/* node '/iomuxc@443c0000/IOMUXC1_SD1_DATA5_GPIO_IO_GPIO3_IO15' defined in modules/hal/nxp/dts/nxp/nxp_imx/mimx9111cvxxj-pinctrl.dtsi:1133 */
		iomuxc1_sd1_data5_gpio_io_gpio3_io15: IOMUXC1_SD1_DATA5_GPIO_IO_GPIO3_IO15 {
			pinmux = < 0x443c0124 0x5 0x0 0x0 0x443c02d4 >; /* in modules/hal/nxp/dts/nxp/nxp_imx/mimx9111cvxxj-pinctrl.dtsi:1134 */
			phandle = < 0x3b >;                             /* in zephyr/dts/arm64/nxp/nxp_mimx9111.dtsi:355 */
		};

		/* node '/iomuxc@443c0000/IOMUXC1_SD1_DATA6_GPIO_IO_GPIO3_IO16' defined in modules/hal/nxp/dts/nxp/nxp_imx/mimx9111cvxxj-pinctrl.dtsi:1151 */
		iomuxc1_sd1_data6_gpio_io_gpio3_io16: IOMUXC1_SD1_DATA6_GPIO_IO_GPIO3_IO16 {
			pinmux = < 0x443c0128 0x5 0x0 0x0 0x443c02d8 >; /* in modules/hal/nxp/dts/nxp/nxp_imx/mimx9111cvxxj-pinctrl.dtsi:1152 */
			phandle = < 0x3c >;                             /* in zephyr/dts/arm64/nxp/nxp_mimx9111.dtsi:355 */
		};

		/* node '/iomuxc@443c0000/IOMUXC1_SD1_DATA7_GPIO_IO_GPIO3_IO17' defined in modules/hal/nxp/dts/nxp/nxp_imx/mimx9111cvxxj-pinctrl.dtsi:1169 */
		iomuxc1_sd1_data7_gpio_io_gpio3_io17: IOMUXC1_SD1_DATA7_GPIO_IO_GPIO3_IO17 {
			pinmux = < 0x443c012c 0x5 0x0 0x0 0x443c02dc >; /* in modules/hal/nxp/dts/nxp/nxp_imx/mimx9111cvxxj-pinctrl.dtsi:1170 */
			phandle = < 0x3d >;                             /* in zephyr/dts/arm64/nxp/nxp_mimx9111.dtsi:355 */
		};

		/* node '/iomuxc@443c0000/IOMUXC1_SD1_STROBE_GPIO_IO_GPIO3_IO18' defined in modules/hal/nxp/dts/nxp/nxp_imx/mimx9111cvxxj-pinctrl.dtsi:1187 */
		iomuxc1_sd1_strobe_gpio_io_gpio3_io18: IOMUXC1_SD1_STROBE_GPIO_IO_GPIO3_IO18 {
			pinmux = < 0x443c0130 0x5 0x0 0x0 0x443c02e0 >; /* in modules/hal/nxp/dts/nxp/nxp_imx/mimx9111cvxxj-pinctrl.dtsi:1188 */
			phandle = < 0x3e >;                             /* in zephyr/dts/arm64/nxp/nxp_mimx9111.dtsi:355 */
		};

		/* node '/iomuxc@443c0000/IOMUXC1_SD2_CD_B_GPIO_IO_GPIO3_IO0' defined in modules/hal/nxp/dts/nxp/nxp_imx/mimx9111cvxxj-pinctrl.dtsi:1199 */
		iomuxc1_sd2_cd_b_gpio_io_gpio3_io0: IOMUXC1_SD2_CD_B_GPIO_IO_GPIO3_IO0 {
			pinmux = < 0x443c0150 0x5 0x0 0x0 0x443c0300 >; /* in modules/hal/nxp/dts/nxp/nxp_imx/mimx9111cvxxj-pinctrl.dtsi:1200 */
			phandle = < 0x2c >;                             /* in zephyr/dts/arm64/nxp/nxp_mimx9111.dtsi:355 */
		};

		/* node '/iomuxc@443c0000/IOMUXC1_SD2_CLK_GPIO_IO_GPIO3_IO1' defined in modules/hal/nxp/dts/nxp/nxp_imx/mimx9111cvxxj-pinctrl.dtsi:1217 */
		iomuxc1_sd2_clk_gpio_io_gpio3_io1: IOMUXC1_SD2_CLK_GPIO_IO_GPIO3_IO1 {
			pinmux = < 0x443c0154 0x5 0x0 0x0 0x443c0304 >; /* in modules/hal/nxp/dts/nxp/nxp_imx/mimx9111cvxxj-pinctrl.dtsi:1218 */
			phandle = < 0x2d >;                             /* in zephyr/dts/arm64/nxp/nxp_mimx9111.dtsi:355 */
		};

		/* node '/iomuxc@443c0000/IOMUXC1_SD2_CMD_GPIO_IO_GPIO3_IO2' defined in modules/hal/nxp/dts/nxp/nxp_imx/mimx9111cvxxj-pinctrl.dtsi:1235 */
		iomuxc1_sd2_cmd_gpio_io_gpio3_io2: IOMUXC1_SD2_CMD_GPIO_IO_GPIO3_IO2 {
			pinmux = < 0x443c0158 0x5 0x0 0x0 0x443c0308 >; /* in modules/hal/nxp/dts/nxp/nxp_imx/mimx9111cvxxj-pinctrl.dtsi:1236 */
			phandle = < 0x2e >;                             /* in zephyr/dts/arm64/nxp/nxp_mimx9111.dtsi:355 */
		};

		/* node '/iomuxc@443c0000/IOMUXC1_SD2_DATA0_GPIO_IO_GPIO3_IO3' defined in modules/hal/nxp/dts/nxp/nxp_imx/mimx9111cvxxj-pinctrl.dtsi:1256 */
		iomuxc1_sd2_data0_gpio_io_gpio3_io3: IOMUXC1_SD2_DATA0_GPIO_IO_GPIO3_IO3 {
			pinmux = < 0x443c015c 0x5 0x0 0x0 0x443c030c >; /* in modules/hal/nxp/dts/nxp/nxp_imx/mimx9111cvxxj-pinctrl.dtsi:1257 */
			phandle = < 0x2f >;                             /* in zephyr/dts/arm64/nxp/nxp_mimx9111.dtsi:355 */
		};

		/* node '/iomuxc@443c0000/IOMUXC1_SD2_DATA1_GPIO_IO_GPIO3_IO4' defined in modules/hal/nxp/dts/nxp/nxp_imx/mimx9111cvxxj-pinctrl.dtsi:1274 */
		iomuxc1_sd2_data1_gpio_io_gpio3_io4: IOMUXC1_SD2_DATA1_GPIO_IO_GPIO3_IO4 {
			pinmux = < 0x443c0160 0x5 0x0 0x0 0x443c0310 >; /* in modules/hal/nxp/dts/nxp/nxp_imx/mimx9111cvxxj-pinctrl.dtsi:1275 */
			phandle = < 0x30 >;                             /* in zephyr/dts/arm64/nxp/nxp_mimx9111.dtsi:355 */
		};

		/* node '/iomuxc@443c0000/IOMUXC1_SD2_DATA2_GPIO_IO_GPIO3_IO5' defined in modules/hal/nxp/dts/nxp/nxp_imx/mimx9111cvxxj-pinctrl.dtsi:1289 */
		iomuxc1_sd2_data2_gpio_io_gpio3_io5: IOMUXC1_SD2_DATA2_GPIO_IO_GPIO3_IO5 {
			pinmux = < 0x443c0164 0x5 0x0 0x0 0x443c0314 >; /* in modules/hal/nxp/dts/nxp/nxp_imx/mimx9111cvxxj-pinctrl.dtsi:1290 */
			phandle = < 0x31 >;                             /* in zephyr/dts/arm64/nxp/nxp_mimx9111.dtsi:355 */
		};

		/* node '/iomuxc@443c0000/IOMUXC1_SD2_DATA3_GPIO_IO_GPIO3_IO6' defined in modules/hal/nxp/dts/nxp/nxp_imx/mimx9111cvxxj-pinctrl.dtsi:1304 */
		iomuxc1_sd2_data3_gpio_io_gpio3_io6: IOMUXC1_SD2_DATA3_GPIO_IO_GPIO3_IO6 {
			pinmux = < 0x443c0168 0x5 0x0 0x0 0x443c0318 >; /* in modules/hal/nxp/dts/nxp/nxp_imx/mimx9111cvxxj-pinctrl.dtsi:1305 */
			phandle = < 0x32 >;                             /* in zephyr/dts/arm64/nxp/nxp_mimx9111.dtsi:355 */
		};

		/* node '/iomuxc@443c0000/IOMUXC1_SD2_RESET_B_GPIO_IO_GPIO3_IO7' defined in modules/hal/nxp/dts/nxp/nxp_imx/mimx9111cvxxj-pinctrl.dtsi:1325 */
		iomuxc1_sd2_reset_b_gpio_io_gpio3_io7: IOMUXC1_SD2_RESET_B_GPIO_IO_GPIO3_IO7 {
			pinmux = < 0x443c016c 0x5 0x0 0x0 0x443c031c >; /* in modules/hal/nxp/dts/nxp/nxp_imx/mimx9111cvxxj-pinctrl.dtsi:1326 */
			phandle = < 0x33 >;                             /* in zephyr/dts/arm64/nxp/nxp_mimx9111.dtsi:355 */
		};

		/* node '/iomuxc@443c0000/IOMUXC1_SD2_VSELECT_GPIO_IO_GPIO3_IO19' defined in modules/hal/nxp/dts/nxp/nxp_imx/mimx9111cvxxj-pinctrl.dtsi:1337 */
		iomuxc1_sd2_vselect_gpio_io_gpio3_io19: IOMUXC1_SD2_VSELECT_GPIO_IO_GPIO3_IO19 {
			pinmux = < 0x443c0134 0x5 0x0 0x0 0x443c02e4 >; /* in modules/hal/nxp/dts/nxp/nxp_imx/mimx9111cvxxj-pinctrl.dtsi:1338 */
			phandle = < 0x3f >;                             /* in zephyr/dts/arm64/nxp/nxp_mimx9111.dtsi:355 */
		};

		/* node '/iomuxc@443c0000/IOMUXC1_SD3_CLK_GPIO_IO_GPIO3_IO20' defined in modules/hal/nxp/dts/nxp/nxp_imx/mimx9111cvxxj-pinctrl.dtsi:1355 */
		iomuxc1_sd3_clk_gpio_io_gpio3_io20: IOMUXC1_SD3_CLK_GPIO_IO_GPIO3_IO20 {
			pinmux = < 0x443c0138 0x5 0x0 0x0 0x443c02e8 >; /* in modules/hal/nxp/dts/nxp/nxp_imx/mimx9111cvxxj-pinctrl.dtsi:1356 */
			phandle = < 0x40 >;                             /* in zephyr/dts/arm64/nxp/nxp_mimx9111.dtsi:355 */
		};

		/* node '/iomuxc@443c0000/IOMUXC1_SD3_CMD_GPIO_IO_GPIO3_IO21' defined in modules/hal/nxp/dts/nxp/nxp_imx/mimx9111cvxxj-pinctrl.dtsi:1370 */
		iomuxc1_sd3_cmd_gpio_io_gpio3_io21: IOMUXC1_SD3_CMD_GPIO_IO_GPIO3_IO21 {
			pinmux = < 0x443c013c 0x5 0x0 0x0 0x443c02ec >; /* in modules/hal/nxp/dts/nxp/nxp_imx/mimx9111cvxxj-pinctrl.dtsi:1371 */
			phandle = < 0x41 >;                             /* in zephyr/dts/arm64/nxp/nxp_mimx9111.dtsi:355 */
		};

		/* node '/iomuxc@443c0000/IOMUXC1_SD3_DATA0_GPIO_IO_GPIO3_IO22' defined in modules/hal/nxp/dts/nxp/nxp_imx/mimx9111cvxxj-pinctrl.dtsi:1385 */
		iomuxc1_sd3_data0_gpio_io_gpio3_io22: IOMUXC1_SD3_DATA0_GPIO_IO_GPIO3_IO22 {
			pinmux = < 0x443c0140 0x5 0x0 0x0 0x443c02f0 >; /* in modules/hal/nxp/dts/nxp/nxp_imx/mimx9111cvxxj-pinctrl.dtsi:1386 */
			phandle = < 0x42 >;                             /* in zephyr/dts/arm64/nxp/nxp_mimx9111.dtsi:355 */
		};

		/* node '/iomuxc@443c0000/IOMUXC1_SD3_DATA1_GPIO_IO_GPIO3_IO23' defined in modules/hal/nxp/dts/nxp/nxp_imx/mimx9111cvxxj-pinctrl.dtsi:1400 */
		iomuxc1_sd3_data1_gpio_io_gpio3_io23: IOMUXC1_SD3_DATA1_GPIO_IO_GPIO3_IO23 {
			pinmux = < 0x443c0144 0x5 0x0 0x0 0x443c02f4 >; /* in modules/hal/nxp/dts/nxp/nxp_imx/mimx9111cvxxj-pinctrl.dtsi:1401 */
			phandle = < 0x43 >;                             /* in zephyr/dts/arm64/nxp/nxp_mimx9111.dtsi:355 */
		};

		/* node '/iomuxc@443c0000/IOMUXC1_SD3_DATA2_GPIO_IO_GPIO3_IO24' defined in modules/hal/nxp/dts/nxp/nxp_imx/mimx9111cvxxj-pinctrl.dtsi:1415 */
		iomuxc1_sd3_data2_gpio_io_gpio3_io24: IOMUXC1_SD3_DATA2_GPIO_IO_GPIO3_IO24 {
			pinmux = < 0x443c0148 0x5 0x0 0x0 0x443c02f8 >; /* in modules/hal/nxp/dts/nxp/nxp_imx/mimx9111cvxxj-pinctrl.dtsi:1416 */
			phandle = < 0x44 >;                             /* in zephyr/dts/arm64/nxp/nxp_mimx9111.dtsi:355 */
		};

		/* node '/iomuxc@443c0000/IOMUXC1_SD3_DATA3_GPIO_IO_GPIO3_IO25' defined in modules/hal/nxp/dts/nxp/nxp_imx/mimx9111cvxxj-pinctrl.dtsi:1430 */
		iomuxc1_sd3_data3_gpio_io_gpio3_io25: IOMUXC1_SD3_DATA3_GPIO_IO_GPIO3_IO25 {
			pinmux = < 0x443c014c 0x5 0x0 0x0 0x443c02fc >; /* in modules/hal/nxp/dts/nxp/nxp_imx/mimx9111cvxxj-pinctrl.dtsi:1431 */
			phandle = < 0x45 >;                             /* in zephyr/dts/arm64/nxp/nxp_mimx9111.dtsi:355 */
		};

		/* node '/iomuxc@443c0000/IOMUXC1_UART1_RXD_GPIO_IO_GPIO1_IO4' defined in modules/hal/nxp/dts/nxp/nxp_imx/mimx9111cvxxj-pinctrl.dtsi:1442 */
		iomuxc1_uart1_rxd_gpio_io_gpio1_io4: IOMUXC1_UART1_RXD_GPIO_IO_GPIO1_IO4 {
			pinmux = < 0x443c0180 0x5 0x0 0x0 0x443c0330 >; /* in modules/hal/nxp/dts/nxp/nxp_imx/mimx9111cvxxj-pinctrl.dtsi:1443 */
			phandle = < 0xa >;                              /* in zephyr/dts/arm64/nxp/nxp_mimx9111.dtsi:311 */
		};

		/* node '/iomuxc@443c0000/IOMUXC1_UART1_RXD_LPUART_RX_LPUART1_RX' defined in modules/hal/nxp/dts/nxp/nxp_imx/mimx9111cvxxj-pinctrl.dtsi:1448 */
		iomuxc1_uart1_rxd_lpuart_rx_lpuart1_rx: IOMUXC1_UART1_RXD_LPUART_RX_LPUART1_RX {
			pinmux = < 0x443c0180 0x0 0x443c0458 0x1 0x443c0330 >; /* in modules/hal/nxp/dts/nxp/nxp_imx/mimx9111cvxxj-pinctrl.dtsi:1449 */
			phandle = < 0x2 >;                                     /* in zephyr/boards/nxp/imx91_qsb/imx91_qsb-pinctrl.dtsi:12 */
		};

		/* node '/iomuxc@443c0000/IOMUXC1_UART1_TXD_GPIO_IO_GPIO1_IO5' defined in modules/hal/nxp/dts/nxp/nxp_imx/mimx9111cvxxj-pinctrl.dtsi:1457 */
		iomuxc1_uart1_txd_gpio_io_gpio1_io5: IOMUXC1_UART1_TXD_GPIO_IO_GPIO1_IO5 {
			pinmux = < 0x443c0184 0x5 0x0 0x0 0x443c0334 >; /* in modules/hal/nxp/dts/nxp/nxp_imx/mimx9111cvxxj-pinctrl.dtsi:1458 */
			phandle = < 0xb >;                              /* in zephyr/dts/arm64/nxp/nxp_mimx9111.dtsi:311 */
		};

		/* node '/iomuxc@443c0000/IOMUXC1_UART1_TXD_LPUART_TX_LPUART1_TX' defined in modules/hal/nxp/dts/nxp/nxp_imx/mimx9111cvxxj-pinctrl.dtsi:1463 */
		iomuxc1_uart1_txd_lpuart_tx_lpuart1_tx: IOMUXC1_UART1_TXD_LPUART_TX_LPUART1_TX {
			pinmux = < 0x443c0184 0x0 0x443c045c 0x1 0x443c0334 >; /* in modules/hal/nxp/dts/nxp/nxp_imx/mimx9111cvxxj-pinctrl.dtsi:1464 */
			phandle = < 0x3 >;                                     /* in zephyr/boards/nxp/imx91_qsb/imx91_qsb-pinctrl.dtsi:12 */
		};

		/* node '/iomuxc@443c0000/IOMUXC1_UART2_RXD_GPIO_IO_GPIO1_IO6' defined in modules/hal/nxp/dts/nxp/nxp_imx/mimx9111cvxxj-pinctrl.dtsi:1469 */
		iomuxc1_uart2_rxd_gpio_io_gpio1_io6: IOMUXC1_UART2_RXD_GPIO_IO_GPIO1_IO6 {
			pinmux = < 0x443c0188 0x5 0x0 0x0 0x443c0338 >; /* in modules/hal/nxp/dts/nxp/nxp_imx/mimx9111cvxxj-pinctrl.dtsi:1470 */
			phandle = < 0xc >;                              /* in zephyr/dts/arm64/nxp/nxp_mimx9111.dtsi:311 */
		};

		/* node '/iomuxc@443c0000/IOMUXC1_UART2_RXD_LPUART_RX_LPUART2_RX' defined in modules/hal/nxp/dts/nxp/nxp_imx/mimx9111cvxxj-pinctrl.dtsi:1478 */
		iomuxc1_uart2_rxd_lpuart_rx_lpuart2_rx: IOMUXC1_UART2_RXD_LPUART_RX_LPUART2_RX {
			pinmux = < 0x443c0188 0x0 0x443c0464 0x1 0x443c0338 >; /* in modules/hal/nxp/dts/nxp/nxp_imx/mimx9111cvxxj-pinctrl.dtsi:1479 */
			phandle = < 0x4 >;                                     /* in zephyr/boards/nxp/imx91_qsb/imx91_qsb-pinctrl.dtsi:22 */
		};

		/* node '/iomuxc@443c0000/IOMUXC1_UART2_TXD_GPIO_IO_GPIO1_IO7' defined in modules/hal/nxp/dts/nxp/nxp_imx/mimx9111cvxxj-pinctrl.dtsi:1487 */
		iomuxc1_uart2_txd_gpio_io_gpio1_io7: IOMUXC1_UART2_TXD_GPIO_IO_GPIO1_IO7 {
			pinmux = < 0x443c018c 0x5 0x0 0x0 0x443c033c >; /* in modules/hal/nxp/dts/nxp/nxp_imx/mimx9111cvxxj-pinctrl.dtsi:1488 */
			phandle = < 0xd >;                              /* in zephyr/dts/arm64/nxp/nxp_mimx9111.dtsi:311 */
		};

		/* node '/iomuxc@443c0000/IOMUXC1_UART2_TXD_LPUART_TX_LPUART2_TX' defined in modules/hal/nxp/dts/nxp/nxp_imx/mimx9111cvxxj-pinctrl.dtsi:1496 */
		iomuxc1_uart2_txd_lpuart_tx_lpuart2_tx: IOMUXC1_UART2_TXD_LPUART_TX_LPUART2_TX {
			pinmux = < 0x443c018c 0x0 0x443c0468 0x1 0x443c033c >; /* in modules/hal/nxp/dts/nxp/nxp_imx/mimx9111cvxxj-pinctrl.dtsi:1497 */
			phandle = < 0x5 >;                                     /* in zephyr/boards/nxp/imx91_qsb/imx91_qsb-pinctrl.dtsi:22 */
		};

		/* node '/iomuxc@443c0000/IOMUXC1_WDOG_ANY_GPIO_IO_GPIO1_IO15' defined in modules/hal/nxp/dts/nxp/nxp_imx/mimx9111cvxxj-pinctrl.dtsi:1505 */
		iomuxc1_wdog_any_gpio_io_gpio1_io15: IOMUXC1_WDOG_ANY_GPIO_IO_GPIO1_IO15 {
			pinmux = < 0x443c01ac 0x5 0x0 0x0 0x443c035c >; /* in modules/hal/nxp/dts/nxp/nxp_imx/mimx9111cvxxj-pinctrl.dtsi:1506 */
			phandle = < 0x15 >;                             /* in zephyr/dts/arm64/nxp/nxp_mimx9111.dtsi:311 */
		};
	};

	/* node '/ana_pll@44480000' defined in zephyr/dts/arm64/nxp/nxp_mimx9111.dtsi:68 */
	ana_pll: ana_pll@44480000 {
		compatible = "nxp,imx-ana";   /* in zephyr/dts/arm64/nxp/nxp_mimx9111.dtsi:69 */
		reg = < 0x44480000 0x10000 >; /* in zephyr/dts/arm64/nxp/nxp_mimx9111.dtsi:70 */
	};

	/* node '/ccm@44450000' defined in zephyr/dts/arm64/nxp/nxp_mimx9111.dtsi:73 */
	ccm: ccm@44450000 {
		compatible = "nxp,imx-ccm-rev2"; /* in zephyr/dts/arm64/nxp/nxp_mimx9111.dtsi:74 */
		reg = < 0x44450000 0x10000 >;    /* in zephyr/dts/arm64/nxp/nxp_mimx9111.dtsi:75 */
		#clock-cells = < 0x3 >;          /* in zephyr/dts/arm64/nxp/nxp_mimx9111.dtsi:76 */
		phandle = < 0x59 >;              /* in zephyr/dts/arm64/nxp/nxp_mimx9111.dtsi:133 */
	};

	/* node '/gpio@47400000' defined in zephyr/dts/arm64/nxp/nxp_mimx9111.dtsi:79 */
	gpio1: gpio@47400000 {
		compatible = "nxp,imx-rgpio";                             /* in zephyr/dts/arm64/nxp/nxp_mimx9111.dtsi:80 */
		reg = < 0x47400000 0x10000 >;                             /* in zephyr/dts/arm64/nxp/nxp_mimx9111.dtsi:81 */
		interrupt-parent = < &gic >;                              /* in zephyr/dts/arm64/nxp/nxp_mimx9111.dtsi:82 */
		interrupts = < 0x0 0xa 0x2 0xa0 >,
		             < 0x0 0xb 0x2 0xa0 >;                        /* in zephyr/dts/arm64/nxp/nxp_mimx9111.dtsi:83 */
		gpio-controller;                                          /* in zephyr/dts/arm64/nxp/nxp_mimx9111.dtsi:85 */
		#gpio-cells = < 0x2 >;                                    /* in zephyr/dts/arm64/nxp/nxp_mimx9111.dtsi:86 */
		ngpios = < 0x10 >;                                        /* in zephyr/dts/arm64/nxp/nxp_mimx9111.dtsi:87 */
		status = "disabled";                                      /* in zephyr/dts/arm64/nxp/nxp_mimx9111.dtsi:88 */
		pinmux = < &iomuxc1_i2c1_scl_gpio_io_gpio1_io0 >,
		         < &iomuxc1_i2c1_sda_gpio_io_gpio1_io1 >,
		         < &iomuxc1_i2c2_scl_gpio_io_gpio1_io2 >,
		         < &iomuxc1_i2c2_sda_gpio_io_gpio1_io3 >,
		         < &iomuxc1_uart1_rxd_gpio_io_gpio1_io4 >,
		         < &iomuxc1_uart1_txd_gpio_io_gpio1_io5 >,
		         < &iomuxc1_uart2_rxd_gpio_io_gpio1_io6 >,
		         < &iomuxc1_uart2_txd_gpio_io_gpio1_io7 >,
		         < &iomuxc1_pdm_clk_gpio_io_gpio1_io8 >,
		         < &iomuxc1_pdm_bit_stream0_gpio_io_gpio1_io9 >,
		         < &iomuxc1_pdm_bit_stream1_gpio_io_gpio1_io10 >,
		         < &iomuxc1_sai1_txfs_gpio_io_gpio1_io11 >,
		         < &iomuxc1_sai1_txc_gpio_io_gpio1_io12 >,
		         < &iomuxc1_sai1_txd0_gpio_io_gpio1_io13 >,
		         < &iomuxc1_sai1_rxd0_gpio_io_gpio1_io14 >,
		         < &iomuxc1_wdog_any_gpio_io_gpio1_io15 >;        /* in zephyr/dts/arm64/nxp/nxp_mimx9111.dtsi:311 */
	};

	/* node '/gpio@43810000' defined in zephyr/dts/arm64/nxp/nxp_mimx9111.dtsi:91 */
	gpio2: gpio@43810000 {
		compatible = "nxp,imx-rgpio";                       /* in zephyr/dts/arm64/nxp/nxp_mimx9111.dtsi:92 */
		reg = < 0x43810000 0x10000 >;                       /* in zephyr/dts/arm64/nxp/nxp_mimx9111.dtsi:93 */
		interrupt-parent = < &gic >;                        /* in zephyr/dts/arm64/nxp/nxp_mimx9111.dtsi:94 */
		interrupts = < 0x0 0x39 0x2 0xa0 >,
		             < 0x0 0x3a 0x2 0xa0 >;                 /* in zephyr/dts/arm64/nxp/nxp_mimx9111.dtsi:95 */
		gpio-controller;                                    /* in zephyr/dts/arm64/nxp/nxp_mimx9111.dtsi:97 */
		#gpio-cells = < 0x2 >;                              /* in zephyr/dts/arm64/nxp/nxp_mimx9111.dtsi:98 */
		ngpios = < 0x16 >;                                  /* in zephyr/dts/arm64/nxp/nxp_mimx9111.dtsi:99 */
		status = "disabled";                                /* in zephyr/dts/arm64/nxp/nxp_mimx9111.dtsi:100 */
		pinmux = < &iomuxc1_gpio_io00_gpio_io_gpio2_io0 >,
		         < &iomuxc1_gpio_io01_gpio_io_gpio2_io1 >,
		         < &iomuxc1_gpio_io02_gpio_io_gpio2_io2 >,
		         < &iomuxc1_gpio_io03_gpio_io_gpio2_io3 >,
		         < &iomuxc1_gpio_io04_gpio_io_gpio2_io4 >,
		         < &iomuxc1_gpio_io05_gpio_io_gpio2_io5 >,
		         < &iomuxc1_gpio_io06_gpio_io_gpio2_io6 >,
		         < &iomuxc1_gpio_io07_gpio_io_gpio2_io7 >,
		         < &iomuxc1_gpio_io08_gpio_io_gpio2_io8 >,
		         < &iomuxc1_gpio_io09_gpio_io_gpio2_io9 >,
		         < &iomuxc1_gpio_io10_gpio_io_gpio2_io10 >,
		         < &iomuxc1_gpio_io11_gpio_io_gpio2_io11 >,
		         < &iomuxc1_gpio_io12_gpio_io_gpio2_io12 >,
		         < &iomuxc1_gpio_io13_gpio_io_gpio2_io13 >,
		         < &iomuxc1_gpio_io14_gpio_io_gpio2_io14 >,
		         < &iomuxc1_gpio_io15_gpio_io_gpio2_io15 >,
		         < &iomuxc1_gpio_io16_gpio_io_gpio2_io16 >,
		         < &iomuxc1_gpio_io17_gpio_io_gpio2_io17 >,
		         < &iomuxc1_gpio_io18_gpio_io_gpio2_io18 >,
		         < &iomuxc1_gpio_io19_gpio_io_gpio2_io19 >,
		         < &iomuxc1_gpio_io20_gpio_io_gpio2_io20 >,
		         < &iomuxc1_gpio_io21_gpio_io_gpio2_io21 >; /* in zephyr/dts/arm64/nxp/nxp_mimx9111.dtsi:330 */
	};

	/* node '/gpio@43820000' defined in zephyr/dts/arm64/nxp/nxp_mimx9111.dtsi:103 */
	gpio3: gpio@43820000 {
		compatible = "nxp,imx-rgpio";                              /* in zephyr/dts/arm64/nxp/nxp_mimx9111.dtsi:104 */
		reg = < 0x43820000 0x10000 >;                              /* in zephyr/dts/arm64/nxp/nxp_mimx9111.dtsi:105 */
		interrupt-parent = < &gic >;                               /* in zephyr/dts/arm64/nxp/nxp_mimx9111.dtsi:106 */
		interrupts = < 0x0 0x3b 0x2 0xa0 >,
		             < 0x0 0x3c 0x2 0xa0 >;                        /* in zephyr/dts/arm64/nxp/nxp_mimx9111.dtsi:107 */
		gpio-controller;                                           /* in zephyr/dts/arm64/nxp/nxp_mimx9111.dtsi:109 */
		#gpio-cells = < 0x2 >;                                     /* in zephyr/dts/arm64/nxp/nxp_mimx9111.dtsi:110 */
		ngpios = < 0x20 >;                                         /* in zephyr/dts/arm64/nxp/nxp_mimx9111.dtsi:111 */
		status = "disabled";                                       /* in zephyr/dts/arm64/nxp/nxp_mimx9111.dtsi:112 */
		pinmux = < &iomuxc1_sd2_cd_b_gpio_io_gpio3_io0 >,
		         < &iomuxc1_sd2_clk_gpio_io_gpio3_io1 >,
		         < &iomuxc1_sd2_cmd_gpio_io_gpio3_io2 >,
		         < &iomuxc1_sd2_data0_gpio_io_gpio3_io3 >,
		         < &iomuxc1_sd2_data1_gpio_io_gpio3_io4 >,
		         < &iomuxc1_sd2_data2_gpio_io_gpio3_io5 >,
		         < &iomuxc1_sd2_data3_gpio_io_gpio3_io6 >,
		         < &iomuxc1_sd2_reset_b_gpio_io_gpio3_io7 >,
		         < &iomuxc1_sd1_clk_gpio_io_gpio3_io8 >,
		         < &iomuxc1_sd1_cmd_gpio_io_gpio3_io9 >,
		         < &iomuxc1_sd1_data0_gpio_io_gpio3_io10 >,
		         < &iomuxc1_sd1_data1_gpio_io_gpio3_io11 >,
		         < &iomuxc1_sd1_data2_gpio_io_gpio3_io12 >,
		         < &iomuxc1_sd1_data3_gpio_io_gpio3_io13 >,
		         < &iomuxc1_sd1_data4_gpio_io_gpio3_io14 >,
		         < &iomuxc1_sd1_data5_gpio_io_gpio3_io15 >,
		         < &iomuxc1_sd1_data6_gpio_io_gpio3_io16 >,
		         < &iomuxc1_sd1_data7_gpio_io_gpio3_io17 >,
		         < &iomuxc1_sd1_strobe_gpio_io_gpio3_io18 >,
		         < &iomuxc1_sd2_vselect_gpio_io_gpio3_io19 >,
		         < &iomuxc1_sd3_clk_gpio_io_gpio3_io20 >,
		         < &iomuxc1_sd3_cmd_gpio_io_gpio3_io21 >,
		         < &iomuxc1_sd3_data0_gpio_io_gpio3_io22 >,
		         < &iomuxc1_sd3_data1_gpio_io_gpio3_io23 >,
		         < &iomuxc1_sd3_data2_gpio_io_gpio3_io24 >,
		         < &iomuxc1_sd3_data3_gpio_io_gpio3_io25 >,
		         < &iomuxc1_ccm_clko1_gpio_io_gpio3_io26 >,
		         < &iomuxc1_dap_tdi_gpio_io_gpio3_io28 >,
		         < &iomuxc1_dap_tms_swdio_gpio_io_gpio3_io29 >,
		         < &iomuxc1_dap_tclk_swclk_gpio_io_gpio3_io30 >,
		         < &iomuxc1_dap_tdo_traceswo_gpio_io_gpio3_io31 >; /* in zephyr/dts/arm64/nxp/nxp_mimx9111.dtsi:355 */
		gpio-reserved-ranges = < 0x1b 0x1 >;                       /* in zephyr/dts/arm64/nxp/nxp_mimx9111.dtsi:386 */
	};

	/* node '/gpio@43830000' defined in zephyr/dts/arm64/nxp/nxp_mimx9111.dtsi:115 */
	gpio4: gpio@43830000 {
		compatible = "nxp,imx-rgpio";                         /* in zephyr/dts/arm64/nxp/nxp_mimx9111.dtsi:116 */
		reg = < 0x43830000 0x10000 >;                         /* in zephyr/dts/arm64/nxp/nxp_mimx9111.dtsi:117 */
		interrupt-parent = < &gic >;                          /* in zephyr/dts/arm64/nxp/nxp_mimx9111.dtsi:118 */
		interrupts = < 0x0 0xbd 0x2 0xa0 >,
		             < 0x0 0xbe 0x2 0xa0 >;                   /* in zephyr/dts/arm64/nxp/nxp_mimx9111.dtsi:119 */
		gpio-controller;                                      /* in zephyr/dts/arm64/nxp/nxp_mimx9111.dtsi:121 */
		#gpio-cells = < 0x2 >;                                /* in zephyr/dts/arm64/nxp/nxp_mimx9111.dtsi:122 */
		ngpios = < 0xe >;                                     /* in zephyr/dts/arm64/nxp/nxp_mimx9111.dtsi:123 */
		status = "disabled";                                  /* in zephyr/dts/arm64/nxp/nxp_mimx9111.dtsi:124 */
		pinmux = < &iomuxc1_enet1_mdc_gpio_io_gpio4_io0 >,
		         < &iomuxc1_enet1_mdio_gpio_io_gpio4_io1 >,
		         < &iomuxc1_enet1_td3_gpio_io_gpio4_io2 >,
		         < &iomuxc1_enet1_td2_gpio_io_gpio4_io3 >,
		         < &iomuxc1_enet1_td1_gpio_io_gpio4_io4 >,
		         < &iomuxc1_enet1_td0_gpio_io_gpio4_io5 >,
		         < &iomuxc1_enet1_tx_ctl_gpio_io_gpio4_io6 >,
		         < &iomuxc1_enet1_txc_gpio_io_gpio4_io7 >,
		         < &iomuxc1_enet1_rx_ctl_gpio_io_gpio4_io8 >,
		         < &iomuxc1_enet1_rxc_gpio_io_gpio4_io9 >,
		         < &iomuxc1_enet1_rd0_gpio_io_gpio4_io10 >,
		         < &iomuxc1_enet1_rd1_gpio_io_gpio4_io11 >,
		         < &iomuxc1_enet1_rd2_gpio_io_gpio4_io12 >,
		         < &iomuxc1_enet1_rd3_gpio_io_gpio4_io13 >;   /* in zephyr/dts/arm64/nxp/nxp_mimx9111.dtsi:390 */
	};

	/* node '/serial@44380000' defined in zephyr/dts/arm64/nxp/nxp_mimx9111.dtsi:127 */
	lpuart1: serial@44380000 {
		compatible = "nxp,imx-lpuart",
		             "nxp,lpuart";          /* in zephyr/dts/arm64/nxp/nxp_mimx9111.dtsi:128 */
		reg = < 0x44380000 0x10000 >;       /* in zephyr/dts/arm64/nxp/nxp_mimx9111.dtsi:129 */
		interrupts = < 0x0 0x13 0x2 0xa0 >; /* in zephyr/dts/arm64/nxp/nxp_mimx9111.dtsi:130 */
		interrupt-names = "irq_0";          /* in zephyr/dts/arm64/nxp/nxp_mimx9111.dtsi:131 */
		interrupt-parent = < &gic >;        /* in zephyr/dts/arm64/nxp/nxp_mimx9111.dtsi:132 */
		clocks = < &ccm 0x300 0x6c 0x18 >;  /* in zephyr/dts/arm64/nxp/nxp_mimx9111.dtsi:133 */
		status = "okay";                    /* in zephyr/boards/nxp/imx91_qsb/imx91_qsb_mimx9111.dts:30 */
		current-speed = < 0x1c200 >;        /* in zephyr/boards/nxp/imx91_qsb/imx91_qsb_mimx9111.dts:31 */
		pinctrl-0 = < &uart1_default >;     /* in zephyr/boards/nxp/imx91_qsb/imx91_qsb_mimx9111.dts:32 */
		pinctrl-names = "default";          /* in zephyr/boards/nxp/imx91_qsb/imx91_qsb_mimx9111.dts:33 */
	};

	/* node '/serial@44390000' defined in zephyr/dts/arm64/nxp/nxp_mimx9111.dtsi:137 */
	lpuart2: serial@44390000 {
		compatible = "nxp,imx-lpuart",
		             "nxp,lpuart";          /* in zephyr/dts/arm64/nxp/nxp_mimx9111.dtsi:138 */
		reg = < 0x44390000 0x10000 >;       /* in zephyr/dts/arm64/nxp/nxp_mimx9111.dtsi:139 */
		interrupts = < 0x0 0x14 0x2 0xa0 >; /* in zephyr/dts/arm64/nxp/nxp_mimx9111.dtsi:140 */
		interrupt-names = "irq_0";          /* in zephyr/dts/arm64/nxp/nxp_mimx9111.dtsi:141 */
		interrupt-parent = < &gic >;        /* in zephyr/dts/arm64/nxp/nxp_mimx9111.dtsi:142 */
		clocks = < &ccm 0x301 0x6c 0x18 >;  /* in zephyr/dts/arm64/nxp/nxp_mimx9111.dtsi:143 */
		status = "disabled";                /* in zephyr/dts/arm64/nxp/nxp_mimx9111.dtsi:144 */
	};

	/* node '/i2c@44340000' defined in zephyr/dts/arm64/nxp/nxp_mimx9111.dtsi:147 */
	lpi2c1: i2c@44340000 {
		compatible = "nxp,lpi2c";          /* in zephyr/dts/arm64/nxp/nxp_mimx9111.dtsi:148 */
		clock-frequency = < 0x186a0 >;     /* in zephyr/dts/arm64/nxp/nxp_mimx9111.dtsi:149 */
		#address-cells = < 0x1 >;          /* in zephyr/dts/arm64/nxp/nxp_mimx9111.dtsi:150 */
		#size-cells = < 0x0 >;             /* in zephyr/dts/arm64/nxp/nxp_mimx9111.dtsi:151 */
		reg = < 0x44340000 0x4000 >;       /* in zephyr/dts/arm64/nxp/nxp_mimx9111.dtsi:152 */
		interrupts = < 0x0 0xd 0x2 0xa0 >; /* in zephyr/dts/arm64/nxp/nxp_mimx9111.dtsi:153 */
		interrupt-parent = < &gic >;       /* in zephyr/dts/arm64/nxp/nxp_mimx9111.dtsi:154 */
		clocks = < &ccm 0x400 0x70 0x6 >;  /* in zephyr/dts/arm64/nxp/nxp_mimx9111.dtsi:155 */
		status = "disabled";               /* in zephyr/dts/arm64/nxp/nxp_mimx9111.dtsi:156 */
	};

	/* node '/i2c@44350000' defined in zephyr/dts/arm64/nxp/nxp_mimx9111.dtsi:159 */
	lpi2c2: i2c@44350000 {
		compatible = "nxp,lpi2c";          /* in zephyr/dts/arm64/nxp/nxp_mimx9111.dtsi:160 */
		clock-frequency = < 0x186a0 >;     /* in zephyr/dts/arm64/nxp/nxp_mimx9111.dtsi:161 */
		#address-cells = < 0x1 >;          /* in zephyr/dts/arm64/nxp/nxp_mimx9111.dtsi:162 */
		#size-cells = < 0x0 >;             /* in zephyr/dts/arm64/nxp/nxp_mimx9111.dtsi:163 */
		reg = < 0x44350000 0x4000 >;       /* in zephyr/dts/arm64/nxp/nxp_mimx9111.dtsi:164 */
		interrupts = < 0x0 0xe 0x2 0xa0 >; /* in zephyr/dts/arm64/nxp/nxp_mimx9111.dtsi:165 */
		interrupt-parent = < &gic >;       /* in zephyr/dts/arm64/nxp/nxp_mimx9111.dtsi:166 */
		clocks = < &ccm 0x401 0x70 0x8 >;  /* in zephyr/dts/arm64/nxp/nxp_mimx9111.dtsi:167 */
		status = "disabled";               /* in zephyr/dts/arm64/nxp/nxp_mimx9111.dtsi:168 */
	};

	/* node '/i2c@42530000' defined in zephyr/dts/arm64/nxp/nxp_mimx9111.dtsi:171 */
	lpi2c3: i2c@42530000 {
		compatible = "nxp,lpi2c";           /* in zephyr/dts/arm64/nxp/nxp_mimx9111.dtsi:172 */
		clock-frequency = < 0x186a0 >;      /* in zephyr/dts/arm64/nxp/nxp_mimx9111.dtsi:173 */
		#address-cells = < 0x1 >;           /* in zephyr/dts/arm64/nxp/nxp_mimx9111.dtsi:174 */
		#size-cells = < 0x0 >;              /* in zephyr/dts/arm64/nxp/nxp_mimx9111.dtsi:175 */
		reg = < 0x42530000 0x4000 >;        /* in zephyr/dts/arm64/nxp/nxp_mimx9111.dtsi:176 */
		interrupts = < 0x0 0x3e 0x2 0xa0 >; /* in zephyr/dts/arm64/nxp/nxp_mimx9111.dtsi:177 */
		interrupt-parent = < &gic >;        /* in zephyr/dts/arm64/nxp/nxp_mimx9111.dtsi:178 */
		clocks = < &ccm 0x402 0x70 0xa >;   /* in zephyr/dts/arm64/nxp/nxp_mimx9111.dtsi:179 */
		status = "disabled";                /* in zephyr/dts/arm64/nxp/nxp_mimx9111.dtsi:180 */
	};

	/* node '/i2c@42540000' defined in zephyr/dts/arm64/nxp/nxp_mimx9111.dtsi:183 */
	lpi2c4: i2c@42540000 {
		compatible = "nxp,lpi2c";           /* in zephyr/dts/arm64/nxp/nxp_mimx9111.dtsi:184 */
		clock-frequency = < 0x186a0 >;      /* in zephyr/dts/arm64/nxp/nxp_mimx9111.dtsi:185 */
		#address-cells = < 0x1 >;           /* in zephyr/dts/arm64/nxp/nxp_mimx9111.dtsi:186 */
		#size-cells = < 0x0 >;              /* in zephyr/dts/arm64/nxp/nxp_mimx9111.dtsi:187 */
		reg = < 0x42540000 0x4000 >;        /* in zephyr/dts/arm64/nxp/nxp_mimx9111.dtsi:188 */
		interrupts = < 0x0 0x3f 0x2 0xa0 >; /* in zephyr/dts/arm64/nxp/nxp_mimx9111.dtsi:189 */
		interrupt-parent = < &gic >;        /* in zephyr/dts/arm64/nxp/nxp_mimx9111.dtsi:190 */
		clocks = < &ccm 0x403 0x80 0x18 >;  /* in zephyr/dts/arm64/nxp/nxp_mimx9111.dtsi:191 */
		status = "disabled";                /* in zephyr/dts/arm64/nxp/nxp_mimx9111.dtsi:192 */
	};

	/* node '/i2c@426b0000' defined in zephyr/dts/arm64/nxp/nxp_mimx9111.dtsi:195 */
	lpi2c5: i2c@426b0000 {
		compatible = "nxp,lpi2c";           /* in zephyr/dts/arm64/nxp/nxp_mimx9111.dtsi:196 */
		clock-frequency = < 0x186a0 >;      /* in zephyr/dts/arm64/nxp/nxp_mimx9111.dtsi:197 */
		#address-cells = < 0x1 >;           /* in zephyr/dts/arm64/nxp/nxp_mimx9111.dtsi:198 */
		#size-cells = < 0x0 >;              /* in zephyr/dts/arm64/nxp/nxp_mimx9111.dtsi:199 */
		reg = < 0x426b0000 0x4000 >;        /* in zephyr/dts/arm64/nxp/nxp_mimx9111.dtsi:200 */
		interrupts = < 0x0 0xc3 0x2 0xa0 >; /* in zephyr/dts/arm64/nxp/nxp_mimx9111.dtsi:201 */
		interrupt-parent = < &gic >;        /* in zephyr/dts/arm64/nxp/nxp_mimx9111.dtsi:202 */
		clocks = < &ccm 0x404 0x80 0x18 >;  /* in zephyr/dts/arm64/nxp/nxp_mimx9111.dtsi:203 */
		status = "disabled";                /* in zephyr/dts/arm64/nxp/nxp_mimx9111.dtsi:204 */
	};

	/* node '/i2c@426c0000' defined in zephyr/dts/arm64/nxp/nxp_mimx9111.dtsi:207 */
	lpi2c6: i2c@426c0000 {
		compatible = "nxp,lpi2c";           /* in zephyr/dts/arm64/nxp/nxp_mimx9111.dtsi:208 */
		clock-frequency = < 0x186a0 >;      /* in zephyr/dts/arm64/nxp/nxp_mimx9111.dtsi:209 */
		#address-cells = < 0x1 >;           /* in zephyr/dts/arm64/nxp/nxp_mimx9111.dtsi:210 */
		#size-cells = < 0x0 >;              /* in zephyr/dts/arm64/nxp/nxp_mimx9111.dtsi:211 */
		reg = < 0x426c0000 0x4000 >;        /* in zephyr/dts/arm64/nxp/nxp_mimx9111.dtsi:212 */
		interrupts = < 0x0 0xc4 0x2 0xa0 >; /* in zephyr/dts/arm64/nxp/nxp_mimx9111.dtsi:213 */
		interrupt-parent = < &gic >;        /* in zephyr/dts/arm64/nxp/nxp_mimx9111.dtsi:214 */
		clocks = < &ccm 0x405 0x80 0x18 >;  /* in zephyr/dts/arm64/nxp/nxp_mimx9111.dtsi:215 */
		status = "disabled";                /* in zephyr/dts/arm64/nxp/nxp_mimx9111.dtsi:216 */
	};

	/* node '/i2c@426d0000' defined in zephyr/dts/arm64/nxp/nxp_mimx9111.dtsi:219 */
	lpi2c7: i2c@426d0000 {
		compatible = "nxp,lpi2c";           /* in zephyr/dts/arm64/nxp/nxp_mimx9111.dtsi:220 */
		clock-frequency = < 0x186a0 >;      /* in zephyr/dts/arm64/nxp/nxp_mimx9111.dtsi:221 */
		#address-cells = < 0x1 >;           /* in zephyr/dts/arm64/nxp/nxp_mimx9111.dtsi:222 */
		#size-cells = < 0x0 >;              /* in zephyr/dts/arm64/nxp/nxp_mimx9111.dtsi:223 */
		reg = < 0x426d0000 0x4000 >;        /* in zephyr/dts/arm64/nxp/nxp_mimx9111.dtsi:224 */
		interrupts = < 0x0 0xc5 0x2 0xa0 >; /* in zephyr/dts/arm64/nxp/nxp_mimx9111.dtsi:225 */
		interrupt-parent = < &gic >;        /* in zephyr/dts/arm64/nxp/nxp_mimx9111.dtsi:226 */
		clocks = < &ccm 0x406 0x80 0x18 >;  /* in zephyr/dts/arm64/nxp/nxp_mimx9111.dtsi:227 */
		status = "disabled";                /* in zephyr/dts/arm64/nxp/nxp_mimx9111.dtsi:228 */
	};

	/* node '/i2c@426e0000' defined in zephyr/dts/arm64/nxp/nxp_mimx9111.dtsi:231 */
	lpi2c8: i2c@426e0000 {
		compatible = "nxp,lpi2c";           /* in zephyr/dts/arm64/nxp/nxp_mimx9111.dtsi:232 */
		clock-frequency = < 0x186a0 >;      /* in zephyr/dts/arm64/nxp/nxp_mimx9111.dtsi:233 */
		#address-cells = < 0x1 >;           /* in zephyr/dts/arm64/nxp/nxp_mimx9111.dtsi:234 */
		#size-cells = < 0x0 >;              /* in zephyr/dts/arm64/nxp/nxp_mimx9111.dtsi:235 */
		reg = < 0x426e0000 0x4000 >;        /* in zephyr/dts/arm64/nxp/nxp_mimx9111.dtsi:236 */
		interrupts = < 0x0 0xc6 0x2 0xa0 >; /* in zephyr/dts/arm64/nxp/nxp_mimx9111.dtsi:237 */
		interrupt-parent = < &gic >;        /* in zephyr/dts/arm64/nxp/nxp_mimx9111.dtsi:238 */
		clocks = < &ccm 0x407 0x80 0x18 >;  /* in zephyr/dts/arm64/nxp/nxp_mimx9111.dtsi:239 */
		status = "disabled";                /* in zephyr/dts/arm64/nxp/nxp_mimx9111.dtsi:240 */
	};

	/* node '/tpm@44310000' defined in zephyr/dts/arm64/nxp/nxp_mimx9111.dtsi:243 */
	tpm1: tpm@44310000 {
		compatible = "nxp,tpm-timer";       /* in zephyr/dts/arm64/nxp/nxp_mimx9111.dtsi:244 */
		reg = < 0x44310000 0x10000 >;       /* in zephyr/dts/arm64/nxp/nxp_mimx9111.dtsi:245 */
		interrupts = < 0x0 0x24 0x2 0xa0 >; /* in zephyr/dts/arm64/nxp/nxp_mimx9111.dtsi:246 */
		interrupt-names = "irq_0";          /* in zephyr/dts/arm64/nxp/nxp_mimx9111.dtsi:247 */
		interrupt-parent = < &gic >;        /* in zephyr/dts/arm64/nxp/nxp_mimx9111.dtsi:248 */
		clocks = < &ccm 0x1600 0x0 0x0 >;   /* in zephyr/dts/arm64/nxp/nxp_mimx9111.dtsi:249 */
		prescaler = < 0x1 >;                /* in zephyr/dts/arm64/nxp/nxp_mimx9111.dtsi:250 */
		status = "disabled";                /* in zephyr/dts/arm64/nxp/nxp_mimx9111.dtsi:251 */
	};

	/* node '/tpm@44320000' defined in zephyr/dts/arm64/nxp/nxp_mimx9111.dtsi:254 */
	tpm2: tpm@44320000 {
		compatible = "nxp,tpm-timer";       /* in zephyr/dts/arm64/nxp/nxp_mimx9111.dtsi:255 */
		reg = < 0x44320000 0x10000 >;       /* in zephyr/dts/arm64/nxp/nxp_mimx9111.dtsi:256 */
		interrupts = < 0x0 0x25 0x2 0xa0 >; /* in zephyr/dts/arm64/nxp/nxp_mimx9111.dtsi:257 */
		interrupt-names = "irq_0";          /* in zephyr/dts/arm64/nxp/nxp_mimx9111.dtsi:258 */
		interrupt-parent = < &gic >;        /* in zephyr/dts/arm64/nxp/nxp_mimx9111.dtsi:259 */
		clocks = < &ccm 0x1601 0x0 0x0 >;   /* in zephyr/dts/arm64/nxp/nxp_mimx9111.dtsi:260 */
		prescaler = < 0x1 >;                /* in zephyr/dts/arm64/nxp/nxp_mimx9111.dtsi:261 */
		status = "disabled";                /* in zephyr/dts/arm64/nxp/nxp_mimx9111.dtsi:262 */
	};

	/* node '/tpm@424e0000' defined in zephyr/dts/arm64/nxp/nxp_mimx9111.dtsi:265 */
	tpm3: tpm@424e0000 {
		compatible = "nxp,tpm-timer";       /* in zephyr/dts/arm64/nxp/nxp_mimx9111.dtsi:266 */
		reg = < 0x424e0000 0x10000 >;       /* in zephyr/dts/arm64/nxp/nxp_mimx9111.dtsi:267 */
		interrupts = < 0x0 0x4b 0x2 0xa0 >; /* in zephyr/dts/arm64/nxp/nxp_mimx9111.dtsi:268 */
		interrupt-names = "irq_0";          /* in zephyr/dts/arm64/nxp/nxp_mimx9111.dtsi:269 */
		interrupt-parent = < &gic >;        /* in zephyr/dts/arm64/nxp/nxp_mimx9111.dtsi:270 */
		clocks = < &ccm 0x1602 0x0 0x0 >;   /* in zephyr/dts/arm64/nxp/nxp_mimx9111.dtsi:271 */
		prescaler = < 0x1 >;                /* in zephyr/dts/arm64/nxp/nxp_mimx9111.dtsi:272 */
		status = "disabled";                /* in zephyr/dts/arm64/nxp/nxp_mimx9111.dtsi:273 */
	};

	/* node '/tpm@424f0000' defined in zephyr/dts/arm64/nxp/nxp_mimx9111.dtsi:276 */
	tpm4: tpm@424f0000 {
		compatible = "nxp,tpm-timer";       /* in zephyr/dts/arm64/nxp/nxp_mimx9111.dtsi:277 */
		reg = < 0x424f0000 0x10000 >;       /* in zephyr/dts/arm64/nxp/nxp_mimx9111.dtsi:278 */
		interrupts = < 0x0 0x4c 0x2 0xa0 >; /* in zephyr/dts/arm64/nxp/nxp_mimx9111.dtsi:279 */
		interrupt-names = "irq_0";          /* in zephyr/dts/arm64/nxp/nxp_mimx9111.dtsi:280 */
		interrupt-parent = < &gic >;        /* in zephyr/dts/arm64/nxp/nxp_mimx9111.dtsi:281 */
		clocks = < &ccm 0x1603 0x0 0x0 >;   /* in zephyr/dts/arm64/nxp/nxp_mimx9111.dtsi:282 */
		prescaler = < 0x1 >;                /* in zephyr/dts/arm64/nxp/nxp_mimx9111.dtsi:283 */
		status = "disabled";                /* in zephyr/dts/arm64/nxp/nxp_mimx9111.dtsi:284 */
	};

	/* node '/tpm@42500000' defined in zephyr/dts/arm64/nxp/nxp_mimx9111.dtsi:287 */
	tpm5: tpm@42500000 {
		compatible = "nxp,tpm-timer";       /* in zephyr/dts/arm64/nxp/nxp_mimx9111.dtsi:288 */
		reg = < 0x42500000 0x10000 >;       /* in zephyr/dts/arm64/nxp/nxp_mimx9111.dtsi:289 */
		interrupts = < 0x0 0x4d 0x2 0xa0 >; /* in zephyr/dts/arm64/nxp/nxp_mimx9111.dtsi:290 */
		interrupt-names = "irq_0";          /* in zephyr/dts/arm64/nxp/nxp_mimx9111.dtsi:291 */
		interrupt-parent = < &gic >;        /* in zephyr/dts/arm64/nxp/nxp_mimx9111.dtsi:292 */
		clocks = < &ccm 0x1604 0x0 0x0 >;   /* in zephyr/dts/arm64/nxp/nxp_mimx9111.dtsi:293 */
		prescaler = < 0x1 >;                /* in zephyr/dts/arm64/nxp/nxp_mimx9111.dtsi:294 */
		status = "disabled";                /* in zephyr/dts/arm64/nxp/nxp_mimx9111.dtsi:295 */
	};

	/* node '/tpm@42510000' defined in zephyr/dts/arm64/nxp/nxp_mimx9111.dtsi:298 */
	tpm6: tpm@42510000 {
		compatible = "nxp,tpm-timer";       /* in zephyr/dts/arm64/nxp/nxp_mimx9111.dtsi:299 */
		reg = < 0x42510000 0x10000 >;       /* in zephyr/dts/arm64/nxp/nxp_mimx9111.dtsi:300 */
		interrupts = < 0x0 0x4e 0x2 0xa0 >; /* in zephyr/dts/arm64/nxp/nxp_mimx9111.dtsi:301 */
		interrupt-names = "irq_0";          /* in zephyr/dts/arm64/nxp/nxp_mimx9111.dtsi:302 */
		interrupt-parent = < &gic >;        /* in zephyr/dts/arm64/nxp/nxp_mimx9111.dtsi:303 */
		clocks = < &ccm 0x1605 0x0 0x0 >;   /* in zephyr/dts/arm64/nxp/nxp_mimx9111.dtsi:304 */
		prescaler = < 0x1 >;                /* in zephyr/dts/arm64/nxp/nxp_mimx9111.dtsi:305 */
		status = "disabled";                /* in zephyr/dts/arm64/nxp/nxp_mimx9111.dtsi:306 */
	};

	/* node '/memory@80000000' defined in zephyr/boards/nxp/imx91_qsb/imx91_qsb_mimx9111.dts:23 */
	dram: memory@80000000 {
		reg = < 0x80000000 0x100000 >; /* in zephyr/boards/nxp/imx91_qsb/imx91_qsb_mimx9111.dts:24 */
	};
};
